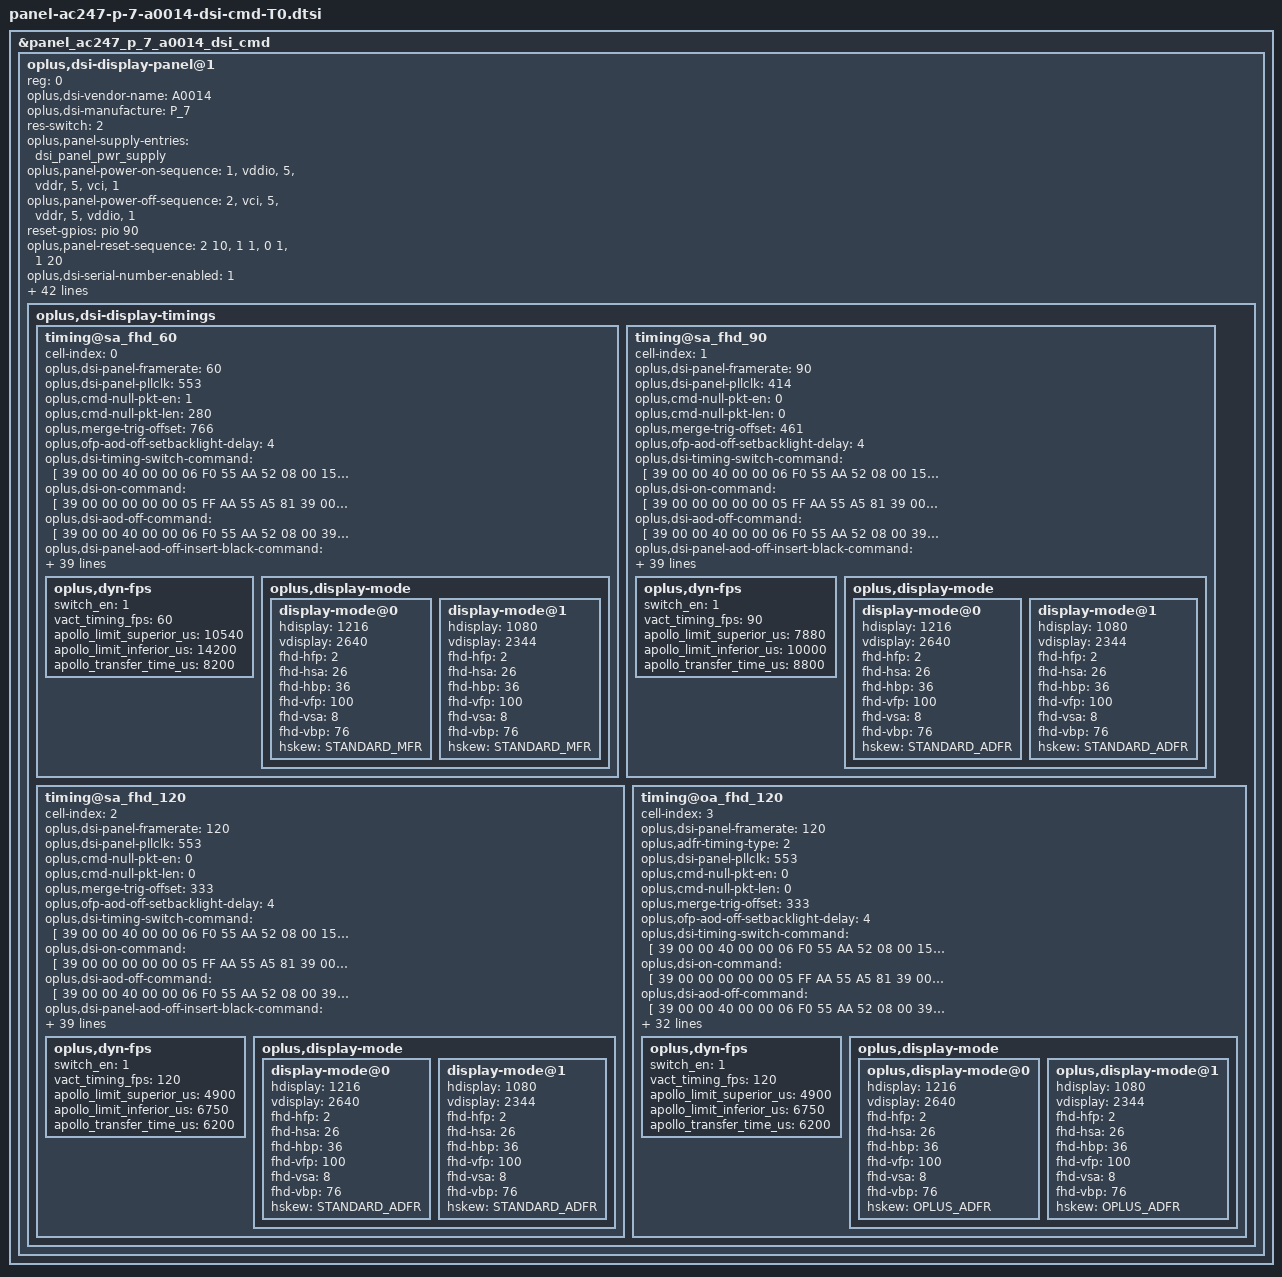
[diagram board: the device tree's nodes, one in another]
&panel_ac247_p_7_a0014_dsi_cmd {
	oplus,dsi-display-panel@1 {
		reg = <0>;
		oplus,dsi-vendor-name = "A0014";
		oplus,dsi-manufacture = "P_7";
		/* round corner */
		//#include "panel-ac247-p-7-a0014-dsi-cmd-round-corner.dtsi"
		oplus,dsi-display-timings {
			timing@sa_fhd_60 {
				cell-index = <0>;
				oplus,dsi-panel-framerate = <60>;
				oplus,dsi-panel-pllclk = <553>;
				oplus,cmd-null-pkt-en = <1>;
				oplus,cmd-null-pkt-len = <280>;
				oplus,merge-trig-offset = <766>;
				oplus,ofp-aod-off-setbacklight-delay = <4>;
				#include "panel-ac247-p-7-a0014-dsi-cmd-common-T0.dtsi"
				oplus,dsi-timing-switch-command = [
					//2F:30->6D:01 60Hz(Repeat 1 times) --> 60Hz
					39 00 00 40 00 00 06 F0 55 AA 52 08 00
					15 00 00 40 00 00 02 6F 03
					39 00 00 40 00 00 03 35 00 01
					15 00 00 40 00 00 02 6F 20
					39 00 00 40 00 00 09 BA 00 01 03 03 00 01 03 03
					15 00 00 40 00 00 02 6F 30
					39 00 00 40 00 00 09 BA 00 01 03 0B 00 01 03 0B
					15 00 00 40 00 00 02 6F 40
					39 00 00 40 00 00 09 BA 00 01 03 17 00 01 03 17
					15 00 00 40 00 00 02 6F 50
					39 00 00 40 00 00 09 BA 00 01 03 77 00 01 03 77
					15 00 00 40 00 00 02 2F 30
					15 00 00 40 00 00 02 6D 01 //60Hz
					// DC/PWM fix
					39 00 00 40 00 00 06 F0 55 AA 52 08 09
					15 00 00 40 00 00 02 6F 1C
					39 00 00 40 00 00 06 BD 90 87 82 06 1C //Comp0_R_Gray0~4_DBV1
					15 00 00 40 00 00 02 6F 21
					39 00 00 40 00 00 06 BD 90 87 82 06 1C //Comp0_R_Gray0~4_DBV2
					15 00 00 40 00 00 02 6F 26
					39 00 00 40 00 00 06 BD 0A 07 02 86 97 //Comp0_R_Gray0~4_DBV3
					15 00 00 40 00 00 02 6F 2B
					39 00 00 40 00 00 06 BD 0A 07 02 86 97 //Comp0_R_Gray0~4_DBV4
					15 00 00 40 00 00 02 6F 3A
					39 00 00 40 00 00 06 BD 90 87 82 06 1C //Comp0_G_Gray0~4_DBV1
					15 00 00 40 00 00 02 6F 3F
					39 00 00 40 00 00 06 BD 90 87 82 06 1C //Comp0_G_Gray0~4_DBV1
					15 00 00 40 00 00 02 6F 44
					39 00 00 40 00 00 06 BD 0A 07 02 86 97 //Comp0_G_Gray0~4_DBV3
					15 00 00 40 00 00 02 6F 49
					39 00 00 40 00 00 06 BD 0A 07 02 86 97 //Comp0_G_Gray0~4_DBV4
					15 00 00 40 00 00 02 6F 58
					39 00 00 40 00 00 06 BD 90 87 82 06 1C //Comp0_B_Gray0~4_DBV1
					15 00 00 40 00 00 02 6F 5D
					39 00 00 40 00 00 06 BD 90 87 82 06 1C //Comp0_B_Gray0~4_DBV1
					15 00 00 40 00 00 02 6F 62
					39 00 00 40 00 00 06 BD 0A 07 02 86 97 //Co mp0_B_Gray0~4_DBV3
					15 00 00 40 00 00 02 6F 67
					39 00 00 00 00 00 06 BD 0A 07 02 86 97 //Comp0_B_Gray0~4_DBV4
				];
				oplus,dsi-on-command = [
					// init code
					39 00 00 00 00 00 05 FF AA 55 A5 81
					39 00 00 00 00 00 02 6F 0C
					39 00 00 00 00 00 02 FD 08
					39 00 00 00 00 00 02 6F 02
					39 00 00 00 00 00 02 F9 84
					39 00 00 00 00 00 02 6F 10
					39 00 00 00 00 00 02 FB 40
					39 00 00 00 00 00 05 FF AA 55 A5 80
					39 00 00 00 00 00 02 6F 48
					39 00 00 00 00 00 02 F2 00
					39 00 00 00 00 00 05 FF AA 55 A5 80
					39 00 00 00 00 00 02 6F 16
					39 00 00 00 00 00 03 F4 02 74
					39 00 00 00 00 00 05 FF AA 55 A5 80
					39 00 00 00 00 00 02 6F 42
					39 00 00 00 00 00 02 F4 00
					39 00 00 00 00 00 05 FF AA 55 A5 80
					39 00 00 00 00 00 02 6F 49
					39 00 00 00 00 00 02 F2 10
					39 00 00 00 00 00 05 FF AA 55 A5 81
					39 00 00 00 00 00 02 6F 05
					39 00 00 00 00 00 03 FE 3C 3C
					39 00 00 00 00 00 05 FF AA 55 A5 82
					39 00 00 00 00 00 02 6F 09
					39 00 00 00 00 00 02 F2 FF
					39 00 00 00 00 00 05 FF AA 55 A5 80
					39 00 00 00 00 00 02 6F 04
					39 00 00 00 00 00 02 F2 3C
					39 00 00 00 00 00 05 FF AA 55 A5 80
					39 00 00 00 00 00 02 6F 0A
					39 00 00 00 00 00 06 F6 70 70 70 70 70 //Power seq
					39 00 00 00 00 00 05 FF AA 55 A5 81
					39 00 00 00 00 00 02 6F 0D
					39 00 00 00 00 00 02 FB 80 // TE_opt
					39 00 00 00 00 00 06 F0 55 AA 52 08 01
					39 00 00 00 00 00 02 E5 00
					39 00 00 00 00 00 05 FF AA 55 A5 80
					39 00 00 00 00 00 02 6F 15
					39 00 00 00 00 00 03 F8 01 8C // DSPOSC=138.6MHz
					39 00 00 00 00 00 05 FF AA 55 A5 80
					39 00 00 00 00 00 02 6F 3E
					39 00 00 00 00 00 02 F8 00
					39 00 00 00 00 00 05 FF AA 55 A5 81
					39 00 00 00 00 00 02 6F 0B
					39 00 00 00 00 00 02 FD 04
					39 00 00 00 00 00 02 5A 01
					39 00 00 00 00 00 02 17 30
					39 00 00 00 00 00 03 5F 00 00
					39 00 00 00 00 00 02 35 00 // TE on
					39 00 00 00 00 00 0A 88 01 02 5F 09 4F 00 00 00 00
					39 00 00 00 00 00 02 53 20
					39 00 00 00 00 00 05 2A 00 00 04 BF
					39 00 00 00 00 00 05 2B 00 00 0A 4F
					39 00 00 00 00 00 02 90 03
					39 00 00 00 00 00 02 6F 01
					39 00 00 00 00 00 02 90 43
					39 00 00 00 00 00 13 91 AB A8 00 14 C2 00 02 31 02 05 00 08 05 0E 04 7B 10 E0 // VESA
					39 00 00 00 00 00 02 26 00
					39 00 00 00 00 00 02 6D 00
					39 00 00 00 00 00 02 6F 06
					39 00 00 00 00 00 02 6D 00
					//Vporch Setting
					39 00 00 00 00 00 06 F0 55 AA 52 08 00
					39 00 00 00 00 00 08 BA 00 59 00 4C 00 64 10
					39 00 00 00 00 00 02 6F 07
					39 00 00 00 00 00 08 BA 00 59 00 4C 04 0C 10
					//Chopper Setting
					39 00 00 00 00 00 06 F0 55 AA 52 08 01
					39 00 00 00 00 00 05 D9 48 50 13 40
					39 00 00 00 00 00 02 6F 23
					39 00 00 00 00 00 04 D9 C1 49 13
					39 00 00 00 00 00 06 F0 55 AA 52 08 08 //alpha LUT
					39 00 00 00 00 00 02 6F 30
					39 00 00 00 00 00 15 B2 00 00 24 B8 2C A8 34 E8 3C 78 23 B7 29 D7 33 D7 3F 27 29 96
					39 00 00 00 00 00 02 6F 44
					39 00 00 00 00 00 15 B2 34 76 22 75 2A 65 32 95 21 E4 20 53 2C E3 2C C3 26 52 20 81
					39 00 00 00 00 00 02 6F 58
					39 00 00 00 00 00 0B B2 31 31 28 30 00 1F 00 1F 00 1F
					39 00 00 00 00 00 02 6F 00
					39 00 00 00 00 00 15 B2 00 01 00 38 00 6F 00 A6 00 DD 01 14 01 5E 01 82 01 B9 01 E0
					39 00 00 00 00 00 02 6F 14
					39 00 00 00 00 00 15 B2 02 27 02 5E 02 95 02 E4 03 E5 04 8A 04 8B 05 DC 07 50 08 FC
					39 00 00 00 00 00 02 6F 28
					39 00 00 00 00 00 09 B2 0B 17 0D BB 0F FE 0F FF
					//odc on/fix
					39 00 00 00 00 00 06 F0 55 AA 52 08 08
					39 00 00 00 00 00 05 E0 21 01 01 01
					15 00 00 00 00 00 02 6F 06
					39 00 00 00 00 00 08 E0 80 30 21 32 43 54 65
					15 00 00 00 00 00 02 6F 0D
					39 00 00 00 00 00 07 E0 76 87 98 99 99 09
					39 00 00 00 00 00 08 E1 00 00 00 00 00 00 00
					15 00 00 00 00 00 02 6F 07
					39 00 00 00 00 00 08 E1 00 00 00 00 00 00 00
					15 00 00 00 00 00 02 6F 0E
					39 00 00 00 00 00 08 E1 00 00 00 00 00 00 00
					15 00 00 00 00 00 02 6F 15
					39 00 00 00 00 00 08 E1 00 00 00 00 00 00 00
					15 00 00 00 00 00 02 6F 1C
					39 00 00 00 00 00 08 E1 00 00 00 00 00 00 00
					15 00 00 00 00 00 02 6F 23
					39 00 00 00 00 00 08 E1 00 00 00 00 00 00 00
					15 00 00 00 00 00 02 6F 2A
					39 00 00 00 00 00 08 E1 00 00 00 00 00 00 00
					15 00 00 00 00 00 02 6F 31
					39 00 00 00 00 00 08 E1 00 00 00 00 00 00 00
					15 00 00 00 00 00 02 6F 38
					39 00 00 00 00 00 08 E1 00 00 00 00 00 00 00
					15 00 00 00 00 00 02 6F 3F
					39 00 00 00 00 00 08 E1 00 00 00 00 00 00 00
					15 00 00 00 00 00 02 6F 46
					39 00 00 00 00 00 08 E1 00 00 00 00 00 00 00
					15 00 00 00 00 00 02 6F 4D
					39 00 00 00 00 00 08 E1 00 00 00 00 00 00 00
					15 00 00 00 00 00 02 6F 54
					39 00 00 00 00 00 08 E1 00 00 00 00 00 00 00
					15 00 00 00 00 00 02 6F 5B
					39 00 00 00 00 00 08 E1 00 00 00 00 00 00 00
					15 00 00 00 00 00 02 6F 62
					39 00 00 00 00 00 08 E1 00 00 00 00 00 00 00
					15 00 00 00 00 00 02 6F 69
					39 00 00 00 00 00 08 E1 00 00 00 00 00 00 00
					15 00 00 00 00 00 02 6F 70
					39 00 00 00 00 00 08 E1 00 00 00 00 00 00 00
					15 00 00 00 00 00 02 6F 77
					39 00 00 00 00 00 08 E1 00 00 00 00 00 00 00
					39 00 00 00 00 00 08 E2 00 00 00 00 00 00 00
					15 00 00 00 00 00 02 6F 07
					39 00 00 00 00 00 08 E2 00 00 00 00 00 00 00
					15 00 00 00 00 00 02 6F 0E
					39 00 00 00 00 00 08 E2 00 00 00 00 00 00 00
					15 00 00 00 00 00 02 6F 15
					39 00 00 00 00 00 08 E2 00 00 00 00 00 00 00
					15 00 00 00 00 00 02 6F 1C
					39 00 00 00 00 00 08 E2 00 00 00 00 00 00 00
					15 00 00 00 00 00 02 6F 23
					39 00 00 00 00 00 08 E2 00 00 00 00 00 00 00
					15 00 00 00 00 00 02 6F 2A
					39 00 00 00 00 00 08 E2 02 04 0A 07 08 08 08
					15 00 00 00 00 00 02 6F 31
					39 00 00 00 00 00 08 E2 02 04 0A 07 08 08 08
					15 00 00 00 00 00 02 6F 38
					39 00 00 00 00 00 08 E2 02 04 0A 07 08 08 08
					15 00 00 00 00 00 02 6F 3F
					39 00 00 00 00 00 08 E2 02 04 0A 07 08 08 08
					15 00 00 00 00 00 02 6F 46
					39 00 00 00 00 00 08 E2 00 00 06 01 03 06 08
					15 00 00 00 00 00 02 6F 4D
					39 00 00 00 00 00 08 E2 02 04 0A 07 08 08 08
					15 00 00 00 00 00 02 6F 54
					39 00 00 00 00 00 08 E2 06 06 06 06 06 06 06
					15 00 00 00 00 00 02 6F 5B
					39 00 00 00 00 00 08 E2 06 06 06 06 06 06 06
					15 00 00 00 00 00 02 6F 62
					39 00 00 00 00 00 08 E2 06 06 06 06 06 06 06
					15 00 00 00 00 00 02 6F 69
					39 00 00 00 00 00 08 E2 06 06 06 06 06 06 06
					15 00 00 00 00 00 02 6F 70
					39 00 00 00 00 00 08 E2 07 07 07 07 07 07 07
					15 00 00 00 00 00 02 6F 77
					39 00 00 00 00 00 08 E2 07 07 07 07 07 07 07
					39 00 00 00 00 00 08 E3 00 00 00 00 00 00 00
					15 00 00 00 00 00 02 6F 07
					39 00 00 00 00 00 08 E3 00 00 00 00 00 00 00
					15 00 00 00 00 00 02 6F 0E
					39 00 00 00 00 00 08 E3 00 00 00 00 00 00 00
					15 00 00 00 00 00 02 6F 15
					39 00 00 00 00 00 08 E3 00 00 00 00 00 00 00
					15 00 00 00 00 00 02 6F 1C
					39 00 00 00 00 00 08 E3 00 00 00 00 00 00 00
					15 00 00 00 00 00 02 6F 23
					39 00 00 00 00 00 08 E3 00 00 00 00 00 00 00
					15 00 00 00 00 00 02 6F 2A
					39 00 00 00 00 00 08 E3 00 00 00 00 00 00 00
					15 00 00 00 00 00 02 6F 31
					39 00 00 00 00 00 08 E3 00 00 00 00 00 00 00
					15 00 00 00 00 00 02 6F 38
					39 00 00 00 00 00 08 E3 00 00 00 00 00 00 00
					15 00 00 00 00 00 02 6F 3F
					39 00 00 00 00 00 08 E3 00 00 00 00 00 00 00
					15 00 00 00 00 00 02 6F 46
					39 00 00 00 00 00 08 E3 00 00 00 00 00 00 00
					15 00 00 00 00 00 02 6F 4D
					39 00 00 00 00 00 08 E3 00 00 00 00 00 00 00
					15 00 00 00 00 00 02 6F 54
					39 00 00 00 00 00 08 E3 00 00 00 00 00 00 00
					15 00 00 00 00 00 02 6F 5B
					39 00 00 00 00 00 08 E3 00 00 00 00 00 00 00
					15 00 00 00 00 00 02 6F 62
					39 00 00 00 00 00 08 E3 00 00 00 00 00 00 00
					15 00 00 00 00 00 02 6F 69
					39 00 00 00 00 00 08 E3 00 00 00 00 00 00 00
					15 00 00 00 00 00 02 6F 70
					39 00 00 00 00 00 08 E3 00 00 00 00 00 00 00
					15 00 00 00 00 00 02 6F 77
					39 00 00 00 00 00 08 E3 00 00 00 00 00 00 00
					39 00 00 00 00 00 08 EA 00 00 00 00 00 00 00
					15 00 00 00 00 00 02 6F 07
					39 00 00 00 00 00 08 EA 00 00 00 00 00 00 00
					15 00 00 00 00 00 02 6F 0E
					39 00 00 00 00 00 08 EA 00 00 00 00 00 00 00
					15 00 00 00 00 00 02 6F 15
					39 00 00 00 00 00 07 EA 00 00 00 00 00 00
					39 00 00 00 00 00 08 E4 00 00 00 00 00 00 00
					15 00 00 00 00 00 02 6F 07
					39 00 00 00 00 00 03 E4 00 00
					39 00 00 00 00 00 08 E5 00 00 00 00 00 00 00
					15 00 00 00 00 00 02 6F 07
					39 00 00 00 00 00 03 E5 00 00
					39 00 00 00 00 00 08 E6 00 00 00 00 00 00 00
					15 00 00 00 00 00 02 6F 07
					39 00 00 00 00 00 03 E6 00 00
					39 00 00 00 00 00 08 E8 11 90 00 00 00 20 00
					15 00 00 00 00 00 02 6F 07
					39 00 00 00 00 00 08 E8 68 6C 6C 70 70 74 74
					15 00 00 00 00 00 02 6F 0E
					39 00 00 00 00 00 08 E8 78 78 7D 7D A0 A0 A1
					15 00 00 00 00 00 02 6F 15
					39 00 00 00 00 00 08 E8 A1 A1 A1 98 98 99 99
					15 00 00 00 00 00 02 6F 1C
					39 00 00 00 00 00 08 E8 99 00 48 4D 4D 4E 4E
					15 00 00 00 00 00 02 6F 23
					39 00 00 00 00 00 08 E8 52 52 56 56 5A 5A 90
					15 00 00 00 00 00 02 6F 2A
					39 00 00 00 00 00 08 E8 90 90 90 90 90 8D 8D
					15 00 00 00 00 00 02 6F 31
					39 00 00 00 00 00 08 E8 89 89 89 00 A8 AA AA
					15 00 00 00 00 00 02 6F 38
					39 00 00 00 00 00 08 E8 AA AA AA AA AB AB AD
					15 00 00 00 00 00 02 6F 3F
					39 00 00 00 00 00 08 E8 AD B8 B8 B8 B8 B8 B8
					15 00 00 00 00 00 02 6F 46
					39 00 00 00 00 00 06 E8 B5 B5 B3 B3 B0
					// serinal number
					39 00 00 00 00 00 06 F0 55 AA 52 08 01
					39 00 00 00 00 00 08 D7 3B 1B 17 24 2F 00 62
					// corner improve
					39 00 00 00 00 00 06 F0 55 AA 52 08 07
					39 00 00 00 00 00 04 C0 07 01 F8
					15 00 00 00 00 00 02 6F 03
					39 00 00 00 00 00 05 C0 00 F0 00 00
					39 00 00 00 00 00 16 C1 3C 00 0C B1 07 39 13 26 3F E7 D0 00 00 00 00 00 00 00 00 00 00
					15 00 00 00 00 00 02 6F 15
					39 00 00 00 00 00 11 C1 83 00 00 2B 9A 9A 21 33 C0 79 2B 00 00 00 00 00
					15 00 00 00 00 00 02 6F 25
					39 00 00 00 00 00 08 C1 00 26 2B AA 22 26 00
					39 00 00 00 00 00 16 C2 3C 00 07 E9 0E 89 15 72 3F F3 84 4C 00 0B 18 A0 00 00 00 00 00
					15 00 00 00 00 00 02 6F 15
					39 00 00 00 00 00 11 C2 04 00 2C B9 AA 22 4F 33 C0 D3 8D 00 00 00 00 00
					15 00 00 00 00 00 02 6F 25
					39 00 00 00 00 00 08 C2 44 94 9A AA 22 29 00
					39 00 00 00 00 00 16 C3 3A 0F 0B 64 06 91 EE B4 00 13 8D 68 00 03 26 1C 7F FC 64 FA 44
					15 00 00 00 00 00 02 6F 15
					39 00 00 00 00 00 11 C3 89 44 94 BF 9A 97 21 33 0F 8A 2B E8 D2 00 00 00
					15 00 00 00 00 00 02 6F 25
					39 00 00 00 00 00 08 C3 00 26 2B 00 29 2D 00
					39 00 00 00 00 00 16 C4 32 0F 07 39 07 E9 F0 E2 00 02 E5 72 00 12 B9 8E 7F FC 76 CF F9
					15 00 00 00 00 00 02 6F 15
					39 00 00 00 00 00 11 C4 2D 44 0C 93 AA 22 4F 33 0F 2D 87 E8 45 00 00 00
					15 00 00 00 00 00 02 6F 25
					39 00 00 00 00 00 08 C4 44 94 99 00 29 2D 00
					39 00 00 00 00 00 16 C5 30 0F 0B D1 07 39 ED 86 3F F2 0E AA 3F F8 61 E2 00 02 02 30 E9
					15 00 00 00 00 00 02 6F 15
					39 00 00 00 00 00 11 C5 02 00 00 2B 00 2E B5 33 F0 79 D5 16 AD 00 00 00
					15 00 00 00 00 00 02 6F 25
					39 00 00 00 00 00 08 C5 44 94 9A 00 26 2D 00
					39 00 00 00 00 00 16 C6 20 0F 07 E9 07 39 F0 E2 3F F7 A8 42 3F F2 37 5E 00 02 33 22 99
					15 00 00 00 00 00 02 6F 15
					39 00 00 00 00 00 11 C6 2D 00 2C B3 00 00 2D 33 F0 D3 79 17 BB 00 00 00
					15 00 00 00 00 00 02 6F 25
					39 00 00 00 00 00 08 C6 00 00 00 00 00 00 00
					39 00 00 00 00 00 16 C7 2E 00 08 A1 07 39 0F CA 00 0A DD 90 3F F5 9E 10 00 00 00 00 00
					15 00 00 00 00 00 02 6F 15
					39 00 00 00 00 00 11 C7 89 44 94 BF 00 2E B7 33 30 89 D5 00 00 00 00 00
					15 00 00 00 00 00 02 6F 25
					39 00 00 00 00 00 08 C7 00 00 00 00 00 00 00
					39 00 00 00 00 00 16 C8 26 00 07 E9 0C B1 14 0A 00 00 00 00 3F E6 B0 00 00 00 00 00 00
					15 00 00 00 00 00 02 6F 15
					39 00 00 00 00 00 11 C8 27 44 0C 93 00 00 2D 33 30 2D 79 00 00 00 00 00
					15 00 00 00 00 00 02 6F 25
					39 00 00 00 00 00 08 C8 00 00 00 00 00 00 00
					39 00 00 00 00 00 16 C9 21 00 05 A4 05 59 00 00 3F FE 5E 98 3F FE 69 94 00 00 1E 2A 04
					15 00 00 00 00 00 02 6F 15
					39 00 00 00 00 00 11 C9 0A 22 3A 5F 00 28 4E 33 F0 DA DB 05 7E 00 00 00
					15 00 00 00 00 00 02 6F 25
					39 00 00 00 00 00 08 C9 00 00 00 00 00 00 00
					39 00 00 00 00 00 16 CA 2D 00 05 A4 05 59 00 00 3F FE 5E 98 00 00 00 00 00 00 00 00 00
					15 00 00 00 00 00 02 6F 15
					39 00 00 00 00 00 11 CA 1B 22 3A 5F 00 4F 75 33 C0 DA 25 00 00 00 00 00
					15 00 00 00 00 00 02 6F 25
					39 00 00 00 00 00 08 CA 00 00 00 00 00 00 00
					39 00 00 00 00 00 16 CB 2B 00 05 A4 05 59 00 00 00 00 00 00 00 00 00 00 7F FF E1 D5 FC
					15 00 00 00 00 00 02 6F 15
					39 00 00 00 00 00 11 CB 1B 22 60 85 00 4F 75 33 0F 26 25 FA 82 00 00 00
					15 00 00 00 00 00 02 6F 25
					39 00 00 00 00 00 08 CB 00 00 00 00 00 00 00
					39 00 00 00 00 00 16 CC 27 00 05 A4 05 59 00 00 00 00 00 00 3F FE 69 94 00 00 00 00 00
					15 00 00 00 00 00 02 6F 15
					39 00 00 00 00 00 11 CC 0A 22 60 85 00 28 4E 33 30 26 DB 00 00 00 00 00
					15 00 00 00 00 00 02 6F 25
					39 00 00 00 00 00 08 CC 00 00 00 00 00 00 00
					39 00 00 00 00 00 16 CD 21 00 27 10 27 10 00 00 3F E1 7B 80 3F E1 7B 80 00 05 F5 E1 00
					15 00 00 00 00 00 02 6F 15
					39 00 00 00 00 00 11 CD 1D 12 FA 5E 89 EB 4F 33 F0 9C 9C 27 10 00 00 00
					15 00 00 00 00 00 02 6F 25
					39 00 00 00 00 00 08 CD 00 00 00 00 00 00 00
					39 00 00 00 00 00 16 CE 27 00 27 10 27 10 00 00 00 00 00 00 3F E1 7B 80 00 00 00 00 00
					15 00 00 00 00 00 02 6F 15
					39 00 00 00 00 00 11 CE 1D 22 5F C3 89 EB 4F 33 30 64 9C 00 00 00 00 00
					15 00 00 00 00 00 02 6F 25
					39 00 00 00 00 00 08 CE 00 00 00 00 00 00 00
					39 00 00 00 00 00 16 CF 2D 00 27 10 27 10 00 00 3F E1 7B 80 00 00 00 00 00 00 00 00 00
					15 00 00 00 00 00 02 6F 15
					39 00 00 00 00 00 11 CF 46 12 FA 5E 99 50 B4 33 C0 9C 64 00 00 00 00 00
					15 00 00 00 00 00 02 6F 25
					39 00 00 00 00 00 08 CF 00 00 00 00 00 00 00
					39 00 00 00 00 00 16 D0 2B 00 27 10 27 10 00 00 00 00 00 00 00 00 00 00 7F FA 0A 1F 00
					15 00 00 00 00 00 02 6F 15
					39 00 00 00 00 00 11 D0 46 22 5F C3 99 50 B4 33 0F 64 64 D8 F0 00 00 00
					15 00 00 00 00 00 02 6F 25
					39 00 00 00 00 00 08 D0 00 00 00 00 00 00 00
					39 00 00 00 00 00 0F D1 7F FC 4B 9A 69 04 BF 7F FB 86 2B AD 04 BF
					15 00 00 00 00 00 02 6F 0E
					39 00 00 00 00 00 0F D1 00 00 00 00 00 04 C0 00 00 00 00 00 04 C0
					15 00 00 00 00 00 02 6F 1C
					39 00 00 00 00 00 0F D1 80 00 00 00 00 04 BF 80 00 00 00 00 04 BF
					15 00 00 00 00 00 02 6F 2A
					39 00 00 00 00 00 0C D1 00 02 11 8A 09 00 00 00 02 33 22
					39 00 00 00 00 00 12 D2 99 00 00 00 00 00 00 00 04 C0 7F FF E1 D5 FC 04 C0
					39 00 00 00 00 00 06 F0 55 AA 52 08 00
					15 00 00 00 00 00 02 6F 13
					39 00 00 00 00 00 19 DF 02 5E 09 4F 00 00 00 00 01 FA 08 EB 02 C3 09 B4 00 00 00 00 00 00 00 00
					//skip sequence
					39 00 00 00 00 00 06 F0 55 AA 52 08 00
					39 00 00 00 00 00 02 6F 1C
					39 00 00 00 00 00 11 BA 01 01 01 01 00 01 03 03 00 01 03 03 00 00 00 00
					39 00 00 00 00 00 02 6F 2C
					39 00 00 00 00 00 11 BA 01 01 01 01 00 01 03 0B 00 01 03 0B 00 00 00 00
					39 00 00 00 00 00 02 6F 3C
					39 00 00 00 00 00 11 BA 01 01 01 01 00 01 03 17 00 01 03 17 00 00 00 00
					39 00 00 00 00 00 02 6F 4C
					39 00 00 00 00 00 11 BA 01 01 01 01 00 01 03 77 00 01 03 77 00 00 00 00
					39 00 00 00 00 00 02 6F 5C
					39 00 00 00 00 00 11 BA 01 01 01 01 01 01 01 01 01 01 01 01 01 01 01 01
					39 00 00 00 00 00 02 6F 6C
					39 00 00 00 00 00 09 BA 00 00 00 00 00 00 00 00
					39 00 00 00 00 00 02 6F 74
					39 00 00 00 00 00 11 BA 00 01 02 03 05 0B 17 77 00 01 02 05 08 11 59 00
					39 00 00 00 00 00 02 6F 84
					39 00 00 00 00 00 11 BA 00 01 02 03 05 0B 17 77 00 01 02 05 08 11 59 00
					39 00 00 00 00 00 02 6F 94
					39 00 00 00 00 00 11 BA 00 00 00 00 00 00 00 00 00 00 00 00 00 00 00 00
					39 00 00 00 00 00 02 6F A4
					39 00 00 00 00 00 11 BA 01 01 01 01 00 00 00 02 00 00 00 03 00 00 00 00
					39 00 00 00 00 00 02 6F B4
					39 00 00 00 00 00 05 BA 94 FA A4 3A
					39 00 00 00 00 00 02 6F B8
					39 00 00 00 00 00 09 BA 00 00 00 00 11 11 11 11
					39 00 00 00 00 00 02 6F C0
					39 00 00 00 00 00 09 BA 10 00 00 00 11 11 11 11
					39 00 00 00 00 00 02 6F 08
					39 00 00 00 00 00 05 BB 01 00 00 00
					39 00 00 00 00 00 02 6F 0C
					39 00 00 00 00 00 05 BB 01 02 02 00
					39 00 00 00 00 00 02 6F 10
					39 00 00 00 00 00 05 BB 01 05 05 00
					39 00 00 00 00 00 02 6F 14
					39 00 00 00 00 00 05 BB 01 00 00 00
					39 00 00 00 00 00 02 6F 18
					39 00 00 00 00 00 06 BB 01 00 1D 1D 00
					39 00 00 00 00 00 02 6F 1D
					39 00 00 00 00 00 05 BB 01 01 01 00
					15 00 00 00 00 00 02 6F 1E
					15 00 00 00 00 00 02 B5 19 // AOD discharge on DVT OTP
					39 00 00 00 00 00 06 F0 55 AA 52 08 08
					15 00 00 00 00 00 02 6F AC
					39 00 00 00 00 00 05 BC 00 10 10 00 // OD beta3 off DVT OTP
					// VFP/VBP SOP/GOP ON
					39 00 00 00 00 00 06 F0 55 AA 52 08 00
					15 00 00 00 00 00 02 6F 0D
					15 00 00 00 00 00 02 C2 0F
					//OSC：121.9-121.2 MHz
					39 00 00 00 00 00 05 FF AA 55 A5 80
					15 00 00 00 00 00 02 6F 31
					39 00 00 00 00 00 03 F8 01 B7
					// LFCC fix
					39 00 00 00 00 00 06 F0 55 AA 52 08 00
					15 00 00 00 00 00 02 6F 08
					15 00 00 00 00 00 02 B2 C0
					39 00 00 00 00 00 06 F0 55 AA 52 08 09
					//Comp_DBVPNTS0~5 = 423h,424h,48Ah,48Bh,4F0h,4F1h
					15 00 00 00 00 00 02 6F 01
					39 00 00 00 00 00 0A BD 44 23 24 44 8A 8B 44 F0 F1
					// Fixed TE
					15 00 00 00 00 00 02 5A 00
					15 00 00 00 00 00 02 6F 03
					15 00 00 00 00 00 02 5A 00
					39 00 00 00 00 00 03 44 00 00
					15 00 00 00 00 00 02 6F 04
					39 00 00 00 00 00 0D 44 00 00 00 00 00 00 00 00 00 00 00 00
					39 00 00 00 00 00 06 F0 55 AA 52 08 00
					15 00 00 00 00 00 02 BE 47
					// TEST TE
					39 00 00 00 00 00 06 F0 55 AA 52 08 00
					15 00 00 00 00 00 02 6F 01
					15 00 00 00 00 00 02 BE 54
					//2F:30->6D:01 60Hz(Repeat 1 times) --> 60Hz
					39 00 00 00 00 00 06 F0 55 AA 52 08 00
					15 00 00 00 00 00 02 6F 03
					39 00 00 00 00 00 03 35 00 01
					15 00 00 00 00 00 02 6F 20
					39 00 00 00 00 00 09 BA 00 01 03 03 00 01 03 03
					15 00 00 00 00 00 02 6F 30
					39 00 00 00 00 00 09 BA 00 01 03 0B 00 01 03 0B
					15 00 00 00 00 00 02 6F 40
					39 00 00 00 00 00 09 BA 00 01 03 17 00 01 03 17
					15 00 00 00 00 00 02 6F 50
					39 00 00 00 00 00 09 BA 00 01 03 77 00 01 03 77
					15 00 00 00 00 00 02 2F 30
					15 00 00 00 00 00 02 6D 01 //60Hz
					// DC/PWM fix
					39 00 00 00 00 00 06 F0 55 AA 52 08 09
					15 00 00 00 00 00 02 6F 1C
					39 00 00 00 00 00 06 BD 90 87 82 06 1C //Comp0_R_Gray0~4_DBV1
					15 00 00 00 00 00 02 6F 21
					39 00 00 00 00 00 06 BD 90 87 82 06 1C //Comp0_R_Gray0~4_DBV2
					15 00 00 00 00 00 02 6F 26
					39 00 00 00 00 00 06 BD 0A 07 02 86 97 //Comp0_R_Gray0~4_DBV3
					15 00 00 00 00 00 02 6F 2B
					39 00 00 00 00 00 06 BD 0A 07 02 86 97 //Comp0_R_Gray0~4_DBV4
					15 00 00 00 00 00 02 6F 3A
					39 00 00 00 00 00 06 BD 90 87 82 06 1C //Comp0_G_Gray0~4_DBV1
					15 00 00 00 00 00 02 6F 3F
					39 00 00 00 00 00 06 BD 90 87 82 06 1C //Comp0_G_Gray0~4_DBV1
					15 00 00 00 00 00 02 6F 44
					39 00 00 00 00 00 06 BD 0A 07 02 86 97 //Comp0_G_Gray0~4_DBV3
					15 00 00 00 00 00 02 6F 49
					39 00 00 00 00 00 06 BD 0A 07 02 86 97 //Comp0_G_Gray0~4_DBV4
					15 00 00 00 00 00 02 6F 58
					39 00 00 00 00 00 06 BD 90 87 82 06 1C //Comp0_B_Gray0~4_DBV1
					15 00 00 00 00 00 02 6F 5D
					39 00 00 00 00 00 06 BD 90 87 82 06 1C //Comp0_B_Gray0~4_DBV1
					15 00 00 00 00 00 02 6F 62
					39 00 00 00 00 00 06 BD 0A 07 02 86 97 //Co mp0_B_Gray0~4_DBV3
					15 00 00 00 00 00 02 6F 67
					39 00 00 00 00 00 06 BD 0A 07 02 86 97 //Comp0_B_Gray0~4_DBV4
					//osc fixed
					39 00 00 00 00 00 06 F0 55 AA 52 08 01
					39 00 00 00 00 00 06 C3 DD 06 20 11 FF
					15 00 00 00 00 00 02 6F 05
					39 00 00 00 00 00 06 C3 00 06 20 11 FF
					15 00 00 00 00 00 02 6F 0A
					39 00 00 00 00 00 06 C3 00 07 0E 20 06
					15 00 00 00 00 00 02 6F 0F
					39 00 00 00 00 00 06 C3 44 19 07 11 18
					15 00 00 00 00 00 02 6F 14
					39 00 00 00 00 00 06 C3 06 5C 13 07 0E
					15 00 00 00 00 00 02 6F 19
					39 00 00 00 00 00 06 C3 20 06 44 19 07
					15 00 00 00 00 00 02 6F 1E
					39 00 00 00 00 00 06 C3 0E 20 06 44 19
					15 00 00 00 00 00 02 6F 23
					39 00 00 00 00 00 06 C3 07 0E 20 06 44
					15 00 00 00 00 00 02 6F 28
					15 00 00 00 00 00 02 C3 19
					//Modify power-off timing
					39 00 00 00 00 00 06 F0 55 AA 52 08 03
					15 00 00 00 00 00 02 6F 07
					15 00 00 00 00 00 02 C6 48
					//Light On
					39 00 00 00 78 00 01 11 // Sleep out
					39 00 00 00 00 00 01 29 // Display out
				];
				oplus,dsi-aod-off-command = [
					39 00 00 40 00 00 06 F0 55 AA 52 08 00
					39 00 00 40 00 00 02 2F 30
					39 00 00 40 00 00 02 6F 03
					39 00 00 40 00 00 03 35 00 01
					39 00 00 40 00 00 02 38 00
					05 00 00 40 00 00 01 2C
					39 00 00 40 00 00 03 51 00 00
					39 00 00 40 00 00 06 F0 55 AA 52 08 08
					39 00 00 40 00 00 02 BE 03
					39 00 00 40 00 00 05 FF AA 55 A5 81
					39 00 00 40 00 00 02 6F 0B
					39 00 00 00 00 00 02 FD 04 //gmaconv on
				];
				oplus,dsi-panel-aod-off-insert-black-command = [
					39 00 00 40 00 00 06 F0 55 AA 52 08 00
					39 00 00 40 00 00 02 C0 66
					39 00 00 40 00 00 06 F0 55 AA 52 08 01
					39 00 00 40 00 00 06 D2 00 11 00 00 15
					39 00 00 40 00 00 02 2F 30
					39 00 00 40 00 00 02 6F 03
					39 00 00 40 00 00 03 35 00 01
					39 00 00 40 00 00 02 38 00
					39 00 00 00 00 00 03 51 00 00
				];
				oplus,dsi-ultra-low-power-aod-on-command = [
					39 00 00 40 00 00 06 F0 55 AA 52 08 00
					39 00 00 40 00 00 02 6F 18
					39 00 00 00 00 00 06 BB 01 00 02 02 00
				];
				oplus,dsi-ultra-low-power-aod-off-command = [
					39 00 00 40 00 00 06 F0 55 AA 52 08 00
					39 00 00 40 00 00 02 6F 18
					39 00 00 00 00 00 06 BB 01 00 00 00 00
				];
				oplus,dsi-hbm-on-command = [
					39 00 00 00 00 00 03 51 0F FE
				];
				oplus,dsi-hbm-off-command = [
					39 00 00 00 00 00 03 51 0D BB
				];
				oplus,dsi-adfr-min-fps-60hz-command = [
					39 00 00 40 00 00 06 F0 55 AA 52 08 09
					15 00 00 40 00 00 02 6F 1C
					39 00 00 40 00 00 06 BD 90 87 82 06 1C
					15 00 00 40 00 00 02 6F 21
					39 00 00 40 00 00 06 BD 90 87 82 06 1C
					15 00 00 40 00 00 02 6F 26
					39 00 00 40 00 00 06 BD 0A 07 02 86 97
					15 00 00 40 00 00 02 6F 2B
					39 00 00 40 00 00 06 BD 0A 07 02 86 97
					15 00 00 40 00 00 02 6F 3A
					39 00 00 40 00 00 06 BD 90 87 82 06 1C
					15 00 00 40 00 00 02 6F 3F
					39 00 00 40 00 00 06 BD 90 87 82 06 1C
					15 00 00 40 00 00 02 6F 44
					39 00 00 40 00 00 06 BD 0A 07 02 86 97
					15 00 00 40 00 00 02 6F 49
					39 00 00 40 00 00 06 BD 0A 07 02 86 97
					15 00 00 40 00 00 02 6F 58
					39 00 00 40 00 00 06 BD 90 87 82 06 1C
					15 00 00 40 00 00 02 6F 5D
					39 00 00 40 00 00 06 BD 90 87 82 06 1C
					15 00 00 40 00 00 02 6F 62
					39 00 00 40 00 00 06 BD 0A 07 02 86 97
					15 00 00 40 00 00 02 6F 67
					39 00 00 40 00 00 06 BD 0A 07 02 86 97
					39 00 00 40 00 00 02 2F 30
					39 00 00 00 00 00 02 6D 01
				];
				oplus,dsi-adfr-min-fps-30hz-command = [
					39 00 00 40 00 00 06 F0 55 AA 52 08 09
					15 00 00 40 00 00 02 6F 1C
					39 00 00 40 00 00 06 BD 90 87 82 06 1C
					15 00 00 40 00 00 02 6F 21
					39 00 00 40 00 00 06 BD 90 87 82 06 1C
					15 00 00 40 00 00 02 6F 26
					39 00 00 40 00 00 06 BD 0A 07 02 86 97
					15 00 00 40 00 00 02 6F 2B
					39 00 00 40 00 00 06 BD 0A 07 02 86 97
					15 00 00 40 00 00 02 6F 3A
					39 00 00 40 00 00 06 BD 90 87 82 06 1C
					15 00 00 40 00 00 02 6F 3F
					39 00 00 40 00 00 06 BD 90 87 82 06 1C
					15 00 00 40 00 00 02 6F 44
					39 00 00 40 00 00 06 BD 0A 07 02 86 97
					15 00 00 40 00 00 02 6F 49
					39 00 00 40 00 00 06 BD 0A 07 02 86 97
					15 00 00 40 00 00 02 6F 58
					39 00 00 40 00 00 06 BD 90 87 82 06 1C
					15 00 00 40 00 00 02 6F 5D
					39 00 00 40 00 00 06 BD 90 87 82 06 1C
					15 00 00 40 00 00 02 6F 62
					39 00 00 40 00 00 06 BD 0A 07 02 86 97
					15 00 00 40 00 00 02 6F 67
					39 00 00 40 00 00 06 BD 0A 07 02 86 97
					39 00 00 40 00 00 02 2F 30
					39 00 00 00 00 00 02 6D 03
				];
				oplus,dsi-adfr-min-fps-10hz-command = [
					39 00 00 40 00 00 06 F0 55 AA 52 08 09
					15 00 00 40 00 00 02 6F 1C
					39 00 00 40 00 00 06 BD 90 87 82 06 1C
					15 00 00 40 00 00 02 6F 21
					39 00 00 40 00 00 06 BD 90 87 82 06 1C
					15 00 00 40 00 00 02 6F 26
					39 00 00 40 00 00 06 BD 0A 07 02 86 97
					15 00 00 40 00 00 02 6F 2B
					39 00 00 40 00 00 06 BD 0A 07 02 86 97
					15 00 00 40 00 00 02 6F 3A
					39 00 00 40 00 00 06 BD 90 87 82 06 1C
					15 00 00 40 00 00 02 6F 3F
					39 00 00 40 00 00 06 BD 90 87 82 06 1C
					15 00 00 40 00 00 02 6F 44
					39 00 00 40 00 00 06 BD 0A 07 02 86 97
					15 00 00 40 00 00 02 6F 49
					39 00 00 40 00 00 06 BD 0A 07 02 86 97
					15 00 00 40 00 00 02 6F 58
					39 00 00 40 00 00 06 BD 90 87 82 06 1C
					15 00 00 40 00 00 02 6F 5D
					39 00 00 40 00 00 06 BD 90 87 82 06 1C
					15 00 00 40 00 00 02 6F 62
					39 00 00 40 00 00 06 BD 0A 07 02 86 97
					15 00 00 40 00 00 02 6F 67
					39 00 00 40 00 00 06 BD 0A 07 02 86 97
					39 00 00 40 00 00 02 2F 30
					39 00 00 00 00 00 02 6D 05
				];
				oplus,dsi-adfr-min-fps-1hz-command = [
					39 00 00 40 00 00 06 F0 55 AA 52 08 09
					15 00 00 40 00 00 02 6F 1C
					39 00 00 40 00 00 06 BD 90 87 82 06 1C
					15 00 00 40 00 00 02 6F 21
					39 00 00 40 00 00 06 BD 90 87 82 06 1C
					15 00 00 40 00 00 02 6F 26
					39 00 00 40 00 00 06 BD 0A 07 02 86 97
					15 00 00 40 00 00 02 6F 2B
					39 00 00 40 00 00 06 BD 0A 07 02 86 97
					15 00 00 40 00 00 02 6F 3A
					39 00 00 40 00 00 06 BD 90 87 82 06 1C
					15 00 00 40 00 00 02 6F 3F
					39 00 00 40 00 00 06 BD 90 87 82 06 1C
					15 00 00 40 00 00 02 6F 44
					39 00 00 40 00 00 06 BD 0A 07 02 86 97
					15 00 00 40 00 00 02 6F 49
					39 00 00 40 00 00 06 BD 0A 07 02 86 97
					15 00 00 40 00 00 02 6F 58
					39 00 00 40 00 00 06 BD 90 87 82 06 1C
					15 00 00 40 00 00 02 6F 5D
					39 00 00 40 00 00 06 BD 90 87 82 06 1C
					15 00 00 40 00 00 02 6F 62
					39 00 00 40 00 00 06 BD 0A 07 02 86 97
					15 00 00 40 00 00 02 6F 67
					39 00 00 40 00 00 06 BD 0A 07 02 86 97
					39 00 00 40 00 00 02 2F 30
					39 00 00 00 00 00 02 6D 07
				];
				oplus,dsi-timing-switch-command-state = "dsi_hs_mode";
				oplus,dsi-on-command-state = "dsi_lp_mode";
				oplus,dsi-aod-off-command-state = "dsi_ls_mode";
				oplus,dsi-panel-aod-off-insert-black-command-state = "dsi_ls_mode";
				oplus,dsi-ultra-low-power-aod-on-command-state = "dsi_ls_mode";
				oplus,dsi-ultra-low-power-aod-off-command-state = "dsi_ls_mode";
				oplus,dsi-hbm-on-command-state = "dsi_hs_mode";
				oplus,dsi-hbm-off-command-state = "dsi_hs_mode";
				oplus,dsi-adfr-min-fps-60hz-command-state = "dsi_hs_mode";
				oplus,dsi-adfr-min-fps-30hz-command-state = "dsi_hs_mode";
				oplus,dsi-adfr-min-fps-10hz-command-state = "dsi_hs_mode";
				oplus,dsi-adfr-min-fps-1hz-command-state = "dsi_hs_mode";
				oplus,dsc-params-entries = <&dsc_params>;
				oplus,spr-params-entries = <&spr_params>;
				oplus,dyn-fps {
					switch_en = <1>;
					vact_timing_fps = <60>;
					apollo_limit_superior_us = <10540>;
					apollo_limit_inferior_us = <14200>;
					apollo_transfer_time_us = <8200>;
				};
				oplus,display-mode {
					display-mode@0 {
						hdisplay = <1216>;
						vdisplay = <2640>;
						fhd-hfp = <2>;
						fhd-hsa = <26>;
						fhd-hbp = <36>;
						fhd-vfp = <100>;
						fhd-vsa = <8>;
						fhd-vbp = <76>;
						hskew = <STANDARD_MFR>;
					};
					display-mode@1 {
						hdisplay = <1080>;
						vdisplay = <2344>;
						fhd-hfp = <2>;
						fhd-hsa = <26>;
						fhd-hbp = <36>;
						fhd-vfp = <100>;
						fhd-vsa = <8>;
						fhd-vbp = <76>;
						hskew = <STANDARD_MFR>;
					};
				};
			};
			timing@sa_fhd_90 {
				cell-index = <1>;
				oplus,dsi-panel-framerate = <90>;
				oplus,dsi-panel-pllclk = <414>;
				oplus,cmd-null-pkt-en = <0>;
				oplus,cmd-null-pkt-len = <0>;
				oplus,merge-trig-offset = <461>;
				oplus,ofp-aod-off-setbacklight-delay = <4>;
				#include "panel-ac247-p-7-a0014-dsi-cmd-common-T0.dtsi"
				oplus,dsi-timing-switch-command = [
					//90HZ
					39 00 00 40 00 00 06 F0 55 AA 52 08 00
					15 00 00 40 00 00 02 6F 03
					39 00 00 40 00 00 03 35 00 00
					15 00 00 40 00 00 02 6F 20
					39 00 00 40 00 00 09 BA 00 01 02 02 00 01 02 02
					15 00 00 40 00 00 02 6F 30
					39 00 00 40 00 00 09 BA 00 01 02 08 00 01 02 08
					15 00 00 40 00 00 02 6F 40
					39 00 00 40 00 00 09 BA 00 01 02 11 00 01 02 11
					15 00 00 40 00 00 02 6F 50
					39 00 00 40 00 00 09 BA 00 01 02 59 00 01 02 59
					15 00 00 40 00 00 02 2F 31
					15 00 00 40 00 00 02 6D 08 //90Hz
					// DC/PWM fix
					39 00 00 40 00 00 06 F0 55 AA 52 08 09
					15 00 00 40 00 00 02 6F 1C
					39 00 00 40 00 00 06 BD 98 89 84 02 15 //Comp0_R_Gray0~4_DBV1
					15 00 00 40 00 00 02 6F 21
					39 00 00 40 00 00 06 BD 98 89 84 02 15 //Comp0_R_Gray0~4_DBV2
					15 00 00 40 00 00 02 6F 26
					39 00 00 40 00 00 06 BD 12 09 04 86 97 //Comp0_R_Gray0~4_DBV3
					15 00 00 40 00 00 02 6F 2B
					39 00 00 40 00 00 06 BD 12 09 04 86 97 //Comp0_R_Gray0~4_DBV4
					15 00 00 40 00 00 02 6F 3A
					39 00 00 40 00 00 06 BD 98 89 84 02 15 //Comp0_G_Gray0~4_DBV1
					15 00 00 40 00 00 02 6F 3F
					39 00 00 40 00 00 06 BD 98 89 84 02 15 //Comp0_G_Gray0~4_DBV1
					15 00 00 40 00 00 02 6F 44
					39 00 00 40 00 00 06 BD 12 09 04 86 97 //Comp0_G_Gray0~4_DBV3
					15 00 00 40 00 00 02 6F 49
					39 00 00 40 00 00 06 BD 12 09 04 86 97 //Comp0_G_Gray0~4_DBV4
					15 00 00 40 00 00 02 6F 58
					39 00 00 40 00 00 06 BD 98 89 84 02 15 //Comp 0_B_Gray0~4_DBV1
					15 00 00 40 00 00 02 6F 5D
					39 00 00 40 00 00 06 BD 98 89 84 02 15 //Comp0_B_Gray0~4_DBV1
					15 00 00 40 00 00 02 6F 62
					39 00 00 40 00 00 06 BD 12 09 04 86 97 //Comp0_B_Gray0~4_DBV3
					15 00 00 40 00 00 02 6F 67
					39 00 00 00 00 00 06 BD 12 09 04 86 97 //Comp0_B_Gray0~4_DBV4
				];
				oplus,dsi-on-command = [
					// init code
					39 00 00 00 00 00 05 FF AA 55 A5 81
					39 00 00 00 00 00 02 6F 0C
					39 00 00 00 00 00 02 FD 08
					39 00 00 00 00 00 02 6F 02
					39 00 00 00 00 00 02 F9 84
					39 00 00 00 00 00 02 6F 10
					39 00 00 00 00 00 02 FB 40
					39 00 00 00 00 00 05 FF AA 55 A5 80
					39 00 00 00 00 00 02 6F 48
					39 00 00 00 00 00 02 F2 00
					39 00 00 00 00 00 05 FF AA 55 A5 80
					39 00 00 00 00 00 02 6F 16
					39 00 00 00 00 00 03 F4 02 74
					39 00 00 00 00 00 05 FF AA 55 A5 80
					39 00 00 00 00 00 02 6F 42
					39 00 00 00 00 00 02 F4 00
					39 00 00 00 00 00 05 FF AA 55 A5 80
					39 00 00 00 00 00 02 6F 49
					39 00 00 00 00 00 02 F2 10
					39 00 00 00 00 00 05 FF AA 55 A5 81
					39 00 00 00 00 00 02 6F 05
					39 00 00 00 00 00 03 FE 3C 3C
					39 00 00 00 00 00 05 FF AA 55 A5 82
					39 00 00 00 00 00 02 6F 09
					39 00 00 00 00 00 02 F2 FF
					39 00 00 00 00 00 05 FF AA 55 A5 80
					39 00 00 00 00 00 02 6F 04
					39 00 00 00 00 00 02 F2 3C
					39 00 00 00 00 00 05 FF AA 55 A5 80
					39 00 00 00 00 00 02 6F 0A
					39 00 00 00 00 00 06 F6 70 70 70 70 70 //Power seq
					39 00 00 00 00 00 05 FF AA 55 A5 81
					39 00 00 00 00 00 02 6F 0D
					39 00 00 00 00 00 02 FB 80 // TE_opt
					39 00 00 00 00 00 06 F0 55 AA 52 08 01
					39 00 00 00 00 00 02 E5 00
					39 00 00 00 00 00 05 FF AA 55 A5 80
					39 00 00 00 00 00 02 6F 15
					39 00 00 00 00 00 03 F8 01 8C // DSPOSC=138.6MHz
					39 00 00 00 00 00 05 FF AA 55 A5 80
					39 00 00 00 00 00 02 6F 3E
					39 00 00 00 00 00 02 F8 00
					39 00 00 00 00 00 05 FF AA 55 A5 81
					39 00 00 00 00 00 02 6F 0B
					39 00 00 00 00 00 02 FD 04
					39 00 00 00 00 00 02 5A 01
					39 00 00 00 00 00 02 17 30
					39 00 00 00 00 00 03 5F 00 00
					39 00 00 00 00 00 02 35 00 // TE on
					39 00 00 00 00 00 0A 88 01 02 5F 09 4F 00 00 00 00
					39 00 00 00 00 00 02 53 20
					39 00 00 00 00 00 05 2A 00 00 04 BF
					39 00 00 00 00 00 05 2B 00 00 0A 4F
					39 00 00 00 00 00 02 90 03
					39 00 00 00 00 00 02 6F 01
					39 00 00 00 00 00 02 90 43
					39 00 00 00 00 00 13 91 AB A8 00 14 C2 00 02 31 02 05 00 08 05 0E 04 7B 10 E0 // VESA
					39 00 00 00 00 00 02 26 00
					39 00 00 00 00 00 02 6D 00
					39 00 00 00 00 00 02 6F 06
					39 00 00 00 00 00 02 6D 00
					//Vporch Setting
					39 00 00 00 00 00 06 F0 55 AA 52 08 00
					39 00 00 00 00 00 08 BA 00 59 00 4C 00 64 10
					39 00 00 00 00 00 02 6F 07
					39 00 00 00 00 00 08 BA 00 59 00 4C 04 0C 10
					//Chopper Setting
					39 00 00 00 00 00 06 F0 55 AA 52 08 01
					39 00 00 00 00 00 05 D9 48 50 13 40
					39 00 00 00 00 00 02 6F 23
					39 00 00 00 00 00 04 D9 C1 49 13
					39 00 00 00 00 00 06 F0 55 AA 52 08 08 //alpha LUT
					39 00 00 00 00 00 02 6F 30
					39 00 00 00 00 00 15 B2 00 00 24 B8 2C A8 34 E8 3C 78 23 B7 29 D7 33 D7 3F 27 29 96
					39 00 00 00 00 00 02 6F 44
					39 00 00 00 00 00 15 B2 34 76 22 75 2A 65 32 95 21 E4 20 53 2C E3 2C C3 26 52 20 81
					39 00 00 00 00 00 02 6F 58
					39 00 00 00 00 00 0B B2 31 31 28 30 00 1F 00 1F 00 1F
					39 00 00 00 00 00 02 6F 00
					39 00 00 00 00 00 15 B2 00 01 00 38 00 6F 00 A6 00 DD 01 14 01 5E 01 82 01 B9 01 E0
					39 00 00 00 00 00 02 6F 14
					39 00 00 00 00 00 15 B2 02 27 02 5E 02 95 02 E4 03 E5 04 8A 04 8B 05 DC 07 50 08 FC
					39 00 00 00 00 00 02 6F 28
					39 00 00 00 00 00 09 B2 0B 17 0D BB 0F FE 0F FF
					//odc on/fix
					39 00 00 00 00 00 06 F0 55 AA 52 08 08
					39 00 00 00 00 00 05 E0 21 01 01 01
					15 00 00 00 00 00 02 6F 06
					39 00 00 00 00 00 08 E0 80 30 21 32 43 54 65
					15 00 00 00 00 00 02 6F 0D
					39 00 00 00 00 00 07 E0 76 87 98 99 99 09
					39 00 00 00 00 00 08 E1 00 00 00 00 00 00 00
					15 00 00 00 00 00 02 6F 07
					39 00 00 00 00 00 08 E1 00 00 00 00 00 00 00
					15 00 00 00 00 00 02 6F 0E
					39 00 00 00 00 00 08 E1 00 00 00 00 00 00 00
					15 00 00 00 00 00 02 6F 15
					39 00 00 00 00 00 08 E1 00 00 00 00 00 00 00
					15 00 00 00 00 00 02 6F 1C
					39 00 00 00 00 00 08 E1 00 00 00 00 00 00 00
					15 00 00 00 00 00 02 6F 23
					39 00 00 00 00 00 08 E1 00 00 00 00 00 00 00
					15 00 00 00 00 00 02 6F 2A
					39 00 00 00 00 00 08 E1 00 00 00 00 00 00 00
					15 00 00 00 00 00 02 6F 31
					39 00 00 00 00 00 08 E1 00 00 00 00 00 00 00
					15 00 00 00 00 00 02 6F 38
					39 00 00 00 00 00 08 E1 00 00 00 00 00 00 00
					15 00 00 00 00 00 02 6F 3F
					39 00 00 00 00 00 08 E1 00 00 00 00 00 00 00
					15 00 00 00 00 00 02 6F 46
					39 00 00 00 00 00 08 E1 00 00 00 00 00 00 00
					15 00 00 00 00 00 02 6F 4D
					39 00 00 00 00 00 08 E1 00 00 00 00 00 00 00
					15 00 00 00 00 00 02 6F 54
					39 00 00 00 00 00 08 E1 00 00 00 00 00 00 00
					15 00 00 00 00 00 02 6F 5B
					39 00 00 00 00 00 08 E1 00 00 00 00 00 00 00
					15 00 00 00 00 00 02 6F 62
					39 00 00 00 00 00 08 E1 00 00 00 00 00 00 00
					15 00 00 00 00 00 02 6F 69
					39 00 00 00 00 00 08 E1 00 00 00 00 00 00 00
					15 00 00 00 00 00 02 6F 70
					39 00 00 00 00 00 08 E1 00 00 00 00 00 00 00
					15 00 00 00 00 00 02 6F 77
					39 00 00 00 00 00 08 E1 00 00 00 00 00 00 00
					39 00 00 00 00 00 08 E2 00 00 00 00 00 00 00
					15 00 00 00 00 00 02 6F 07
					39 00 00 00 00 00 08 E2 00 00 00 00 00 00 00
					15 00 00 00 00 00 02 6F 0E
					39 00 00 00 00 00 08 E2 00 00 00 00 00 00 00
					15 00 00 00 00 00 02 6F 15
					39 00 00 00 00 00 08 E2 00 00 00 00 00 00 00
					15 00 00 00 00 00 02 6F 1C
					39 00 00 00 00 00 08 E2 00 00 00 00 00 00 00
					15 00 00 00 00 00 02 6F 23
					39 00 00 00 00 00 08 E2 00 00 00 00 00 00 00
					15 00 00 00 00 00 02 6F 2A
					39 00 00 00 00 00 08 E2 02 04 0A 07 08 08 08
					15 00 00 00 00 00 02 6F 31
					39 00 00 00 00 00 08 E2 02 04 0A 07 08 08 08
					15 00 00 00 00 00 02 6F 38
					39 00 00 00 00 00 08 E2 02 04 0A 07 08 08 08
					15 00 00 00 00 00 02 6F 3F
					39 00 00 00 00 00 08 E2 02 04 0A 07 08 08 08
					15 00 00 00 00 00 02 6F 46
					39 00 00 00 00 00 08 E2 00 00 06 01 03 06 08
					15 00 00 00 00 00 02 6F 4D
					39 00 00 00 00 00 08 E2 02 04 0A 07 08 08 08
					15 00 00 00 00 00 02 6F 54
					39 00 00 00 00 00 08 E2 06 06 06 06 06 06 06
					15 00 00 00 00 00 02 6F 5B
					39 00 00 00 00 00 08 E2 06 06 06 06 06 06 06
					15 00 00 00 00 00 02 6F 62
					39 00 00 00 00 00 08 E2 06 06 06 06 06 06 06
					15 00 00 00 00 00 02 6F 69
					39 00 00 00 00 00 08 E2 06 06 06 06 06 06 06
					15 00 00 00 00 00 02 6F 70
					39 00 00 00 00 00 08 E2 07 07 07 07 07 07 07
					15 00 00 00 00 00 02 6F 77
					39 00 00 00 00 00 08 E2 07 07 07 07 07 07 07
					39 00 00 00 00 00 08 E3 00 00 00 00 00 00 00
					15 00 00 00 00 00 02 6F 07
					39 00 00 00 00 00 08 E3 00 00 00 00 00 00 00
					15 00 00 00 00 00 02 6F 0E
					39 00 00 00 00 00 08 E3 00 00 00 00 00 00 00
					15 00 00 00 00 00 02 6F 15
					39 00 00 00 00 00 08 E3 00 00 00 00 00 00 00
					15 00 00 00 00 00 02 6F 1C
					39 00 00 00 00 00 08 E3 00 00 00 00 00 00 00
					15 00 00 00 00 00 02 6F 23
					39 00 00 00 00 00 08 E3 00 00 00 00 00 00 00
					15 00 00 00 00 00 02 6F 2A
					39 00 00 00 00 00 08 E3 00 00 00 00 00 00 00
					15 00 00 00 00 00 02 6F 31
					39 00 00 00 00 00 08 E3 00 00 00 00 00 00 00
					15 00 00 00 00 00 02 6F 38
					39 00 00 00 00 00 08 E3 00 00 00 00 00 00 00
					15 00 00 00 00 00 02 6F 3F
					39 00 00 00 00 00 08 E3 00 00 00 00 00 00 00
					15 00 00 00 00 00 02 6F 46
					39 00 00 00 00 00 08 E3 00 00 00 00 00 00 00
					15 00 00 00 00 00 02 6F 4D
					39 00 00 00 00 00 08 E3 00 00 00 00 00 00 00
					15 00 00 00 00 00 02 6F 54
					39 00 00 00 00 00 08 E3 00 00 00 00 00 00 00
					15 00 00 00 00 00 02 6F 5B
					39 00 00 00 00 00 08 E3 00 00 00 00 00 00 00
					15 00 00 00 00 00 02 6F 62
					39 00 00 00 00 00 08 E3 00 00 00 00 00 00 00
					15 00 00 00 00 00 02 6F 69
					39 00 00 00 00 00 08 E3 00 00 00 00 00 00 00
					15 00 00 00 00 00 02 6F 70
					39 00 00 00 00 00 08 E3 00 00 00 00 00 00 00
					15 00 00 00 00 00 02 6F 77
					39 00 00 00 00 00 08 E3 00 00 00 00 00 00 00
					39 00 00 00 00 00 08 EA 00 00 00 00 00 00 00
					15 00 00 00 00 00 02 6F 07
					39 00 00 00 00 00 08 EA 00 00 00 00 00 00 00
					15 00 00 00 00 00 02 6F 0E
					39 00 00 00 00 00 08 EA 00 00 00 00 00 00 00
					15 00 00 00 00 00 02 6F 15
					39 00 00 00 00 00 07 EA 00 00 00 00 00 00
					39 00 00 00 00 00 08 E4 00 00 00 00 00 00 00
					15 00 00 00 00 00 02 6F 07
					39 00 00 00 00 00 03 E4 00 00
					39 00 00 00 00 00 08 E5 00 00 00 00 00 00 00
					15 00 00 00 00 00 02 6F 07
					39 00 00 00 00 00 03 E5 00 00
					39 00 00 00 00 00 08 E6 00 00 00 00 00 00 00
					15 00 00 00 00 00 02 6F 07
					39 00 00 00 00 00 03 E6 00 00
					39 00 00 00 00 00 08 E8 11 90 00 00 00 20 00
					15 00 00 00 00 00 02 6F 07
					39 00 00 00 00 00 08 E8 68 6C 6C 70 70 74 74
					15 00 00 00 00 00 02 6F 0E
					39 00 00 00 00 00 08 E8 78 78 7D 7D A0 A0 A1
					15 00 00 00 00 00 02 6F 15
					39 00 00 00 00 00 08 E8 A1 A1 A1 98 98 99 99
					15 00 00 00 00 00 02 6F 1C
					39 00 00 00 00 00 08 E8 99 00 48 4D 4D 4E 4E
					15 00 00 00 00 00 02 6F 23
					39 00 00 00 00 00 08 E8 52 52 56 56 5A 5A 90
					15 00 00 00 00 00 02 6F 2A
					39 00 00 00 00 00 08 E8 90 90 90 90 90 8D 8D
					15 00 00 00 00 00 02 6F 31
					39 00 00 00 00 00 08 E8 89 89 89 00 A8 AA AA
					15 00 00 00 00 00 02 6F 38
					39 00 00 00 00 00 08 E8 AA AA AA AA AB AB AD
					15 00 00 00 00 00 02 6F 3F
					39 00 00 00 00 00 08 E8 AD B8 B8 B8 B8 B8 B8
					15 00 00 00 00 00 02 6F 46
					39 00 00 00 00 00 06 E8 B5 B5 B3 B3 B0
					// serinal number
					39 00 00 00 00 00 06 F0 55 AA 52 08 01
					39 00 00 00 00 00 08 D7 3B 1B 17 24 2F 00 62
					// corner improve
					39 00 00 00 00 00 06 F0 55 AA 52 08 07
					39 00 00 00 00 00 04 C0 07 01 F8
					15 00 00 00 00 00 02 6F 03
					39 00 00 00 00 00 05 C0 00 F0 00 00
					39 00 00 00 00 00 16 C1 3C 00 0C B1 07 39 13 26 3F E7 D0 00 00 00 00 00 00 00 00 00 00
					15 00 00 00 00 00 02 6F 15
					39 00 00 00 00 00 11 C1 83 00 00 2B 9A 9A 21 33 C0 79 2B 00 00 00 00 00
					15 00 00 00 00 00 02 6F 25
					39 00 00 00 00 00 08 C1 00 26 2B AA 22 26 00
					39 00 00 00 00 00 16 C2 3C 00 07 E9 0E 89 15 72 3F F3 84 4C 00 0B 18 A0 00 00 00 00 00
					15 00 00 00 00 00 02 6F 15
					39 00 00 00 00 00 11 C2 04 00 2C B9 AA 22 4F 33 C0 D3 8D 00 00 00 00 00
					15 00 00 00 00 00 02 6F 25
					39 00 00 00 00 00 08 C2 44 94 9A AA 22 29 00
					39 00 00 00 00 00 16 C3 3A 0F 0B 64 06 91 EE B4 00 13 8D 68 00 03 26 1C 7F FC 64 FA 44
					15 00 00 00 00 00 02 6F 15
					39 00 00 00 00 00 11 C3 89 44 94 BF 9A 97 21 33 0F 8A 2B E8 D2 00 00 00
					15 00 00 00 00 00 02 6F 25
					39 00 00 00 00 00 08 C3 00 26 2B 00 29 2D 00
					39 00 00 00 00 00 16 C4 32 0F 07 39 07 E9 F0 E2 00 02 E5 72 00 12 B9 8E 7F FC 76 CF F9
					15 00 00 00 00 00 02 6F 15
					39 00 00 00 00 00 11 C4 2D 44 0C 93 AA 22 4F 33 0F 2D 87 E8 45 00 00 00
					15 00 00 00 00 00 02 6F 25
					39 00 00 00 00 00 08 C4 44 94 99 00 29 2D 00
					39 00 00 00 00 00 16 C5 30 0F 0B D1 07 39 ED 86 3F F2 0E AA 3F F8 61 E2 00 02 02 30 E9
					15 00 00 00 00 00 02 6F 15
					39 00 00 00 00 00 11 C5 02 00 00 2B 00 2E B5 33 F0 79 D5 16 AD 00 00 00
					15 00 00 00 00 00 02 6F 25
					39 00 00 00 00 00 08 C5 44 94 9A 00 26 2D 00
					39 00 00 00 00 00 16 C6 20 0F 07 E9 07 39 F0 E2 3F F7 A8 42 3F F2 37 5E 00 02 33 22 99
					15 00 00 00 00 00 02 6F 15
					39 00 00 00 00 00 11 C6 2D 00 2C B3 00 00 2D 33 F0 D3 79 17 BB 00 00 00
					15 00 00 00 00 00 02 6F 25
					39 00 00 00 00 00 08 C6 00 00 00 00 00 00 00
					39 00 00 00 00 00 16 C7 2E 00 08 A1 07 39 0F CA 00 0A DD 90 3F F5 9E 10 00 00 00 00 00
					15 00 00 00 00 00 02 6F 15
					39 00 00 00 00 00 11 C7 89 44 94 BF 00 2E B7 33 30 89 D5 00 00 00 00 00
					15 00 00 00 00 00 02 6F 25
					39 00 00 00 00 00 08 C7 00 00 00 00 00 00 00
					39 00 00 00 00 00 16 C8 26 00 07 E9 0C B1 14 0A 00 00 00 00 3F E6 B0 00 00 00 00 00 00
					15 00 00 00 00 00 02 6F 15
					39 00 00 00 00 00 11 C8 27 44 0C 93 00 00 2D 33 30 2D 79 00 00 00 00 00
					15 00 00 00 00 00 02 6F 25
					39 00 00 00 00 00 08 C8 00 00 00 00 00 00 00
					39 00 00 00 00 00 16 C9 21 00 05 A4 05 59 00 00 3F FE 5E 98 3F FE 69 94 00 00 1E 2A 04
					15 00 00 00 00 00 02 6F 15
					39 00 00 00 00 00 11 C9 0A 22 3A 5F 00 28 4E 33 F0 DA DB 05 7E 00 00 00
					15 00 00 00 00 00 02 6F 25
					39 00 00 00 00 00 08 C9 00 00 00 00 00 00 00
					39 00 00 00 00 00 16 CA 2D 00 05 A4 05 59 00 00 3F FE 5E 98 00 00 00 00 00 00 00 00 00
					15 00 00 00 00 00 02 6F 15
					39 00 00 00 00 00 11 CA 1B 22 3A 5F 00 4F 75 33 C0 DA 25 00 00 00 00 00
					15 00 00 00 00 00 02 6F 25
					39 00 00 00 00 00 08 CA 00 00 00 00 00 00 00
					39 00 00 00 00 00 16 CB 2B 00 05 A4 05 59 00 00 00 00 00 00 00 00 00 00 7F FF E1 D5 FC
					15 00 00 00 00 00 02 6F 15
					39 00 00 00 00 00 11 CB 1B 22 60 85 00 4F 75 33 0F 26 25 FA 82 00 00 00
					15 00 00 00 00 00 02 6F 25
					39 00 00 00 00 00 08 CB 00 00 00 00 00 00 00
					39 00 00 00 00 00 16 CC 27 00 05 A4 05 59 00 00 00 00 00 00 3F FE 69 94 00 00 00 00 00
					15 00 00 00 00 00 02 6F 15
					39 00 00 00 00 00 11 CC 0A 22 60 85 00 28 4E 33 30 26 DB 00 00 00 00 00
					15 00 00 00 00 00 02 6F 25
					39 00 00 00 00 00 08 CC 00 00 00 00 00 00 00
					39 00 00 00 00 00 16 CD 21 00 27 10 27 10 00 00 3F E1 7B 80 3F E1 7B 80 00 05 F5 E1 00
					15 00 00 00 00 00 02 6F 15
					39 00 00 00 00 00 11 CD 1D 12 FA 5E 89 EB 4F 33 F0 9C 9C 27 10 00 00 00
					15 00 00 00 00 00 02 6F 25
					39 00 00 00 00 00 08 CD 00 00 00 00 00 00 00
					39 00 00 00 00 00 16 CE 27 00 27 10 27 10 00 00 00 00 00 00 3F E1 7B 80 00 00 00 00 00
					15 00 00 00 00 00 02 6F 15
					39 00 00 00 00 00 11 CE 1D 22 5F C3 89 EB 4F 33 30 64 9C 00 00 00 00 00
					15 00 00 00 00 00 02 6F 25
					39 00 00 00 00 00 08 CE 00 00 00 00 00 00 00
					39 00 00 00 00 00 16 CF 2D 00 27 10 27 10 00 00 3F E1 7B 80 00 00 00 00 00 00 00 00 00
					15 00 00 00 00 00 02 6F 15
					39 00 00 00 00 00 11 CF 46 12 FA 5E 99 50 B4 33 C0 9C 64 00 00 00 00 00
					15 00 00 00 00 00 02 6F 25
					39 00 00 00 00 00 08 CF 00 00 00 00 00 00 00
					39 00 00 00 00 00 16 D0 2B 00 27 10 27 10 00 00 00 00 00 00 00 00 00 00 7F FA 0A 1F 00
					15 00 00 00 00 00 02 6F 15
					39 00 00 00 00 00 11 D0 46 22 5F C3 99 50 B4 33 0F 64 64 D8 F0 00 00 00
					15 00 00 00 00 00 02 6F 25
					39 00 00 00 00 00 08 D0 00 00 00 00 00 00 00
					39 00 00 00 00 00 0F D1 7F FC 4B 9A 69 04 BF 7F FB 86 2B AD 04 BF
					15 00 00 00 00 00 02 6F 0E
					39 00 00 00 00 00 0F D1 00 00 00 00 00 04 C0 00 00 00 00 00 04 C0
					15 00 00 00 00 00 02 6F 1C
					39 00 00 00 00 00 0F D1 80 00 00 00 00 04 BF 80 00 00 00 00 04 BF
					15 00 00 00 00 00 02 6F 2A
					39 00 00 00 00 00 0C D1 00 02 11 8A 09 00 00 00 02 33 22
					39 00 00 00 00 00 12 D2 99 00 00 00 00 00 00 00 04 C0 7F FF E1 D5 FC 04 C0
					39 00 00 00 00 00 06 F0 55 AA 52 08 00
					15 00 00 00 00 00 02 6F 13
					39 00 00 00 00 00 19 DF 02 5E 09 4F 00 00 00 00 01 FA 08 EB 02 C3 09 B4 00 00 00 00 00 00 00 00
					//skip sequence
					39 00 00 00 00 00 06 F0 55 AA 52 08 00
					39 00 00 00 00 00 02 6F 1C
					39 00 00 00 00 00 11 BA 01 01 01 01 00 01 03 03 00 01 03 03 00 00 00 00
					39 00 00 00 00 00 02 6F 2C
					39 00 00 00 00 00 11 BA 01 01 01 01 00 01 03 0B 00 01 03 0B 00 00 00 00
					39 00 00 00 00 00 02 6F 3C
					39 00 00 00 00 00 11 BA 01 01 01 01 00 01 03 17 00 01 03 17 00 00 00 00
					39 00 00 00 00 00 02 6F 4C
					39 00 00 00 00 00 11 BA 01 01 01 01 00 01 03 77 00 01 03 77 00 00 00 00
					39 00 00 00 00 00 02 6F 5C
					39 00 00 00 00 00 11 BA 01 01 01 01 01 01 01 01 01 01 01 01 01 01 01 01
					39 00 00 00 00 00 02 6F 6C
					39 00 00 00 00 00 09 BA 00 00 00 00 00 00 00 00
					39 00 00 00 00 00 02 6F 74
					39 00 00 00 00 00 11 BA 00 01 02 03 05 0B 17 77 00 01 02 05 08 11 59 00
					39 00 00 00 00 00 02 6F 84
					39 00 00 00 00 00 11 BA 00 01 02 03 05 0B 17 77 00 01 02 05 08 11 59 00
					39 00 00 00 00 00 02 6F 94
					39 00 00 00 00 00 11 BA 00 00 00 00 00 00 00 00 00 00 00 00 00 00 00 00
					39 00 00 00 00 00 02 6F A4
					39 00 00 00 00 00 11 BA 01 01 01 01 00 00 00 02 00 00 00 03 00 00 00 00
					39 00 00 00 00 00 02 6F B4
					39 00 00 00 00 00 05 BA 94 FA A4 3A
					39 00 00 00 00 00 02 6F B8
					39 00 00 00 00 00 09 BA 00 00 00 00 11 11 11 11
					39 00 00 00 00 00 02 6F C0
					39 00 00 00 00 00 09 BA 10 00 00 00 11 11 11 11
					39 00 00 00 00 00 02 6F 08
					39 00 00 00 00 00 05 BB 01 00 00 00
					39 00 00 00 00 00 02 6F 0C
					39 00 00 00 00 00 05 BB 01 02 02 00
					39 00 00 00 00 00 02 6F 10
					39 00 00 00 00 00 05 BB 01 05 05 00
					39 00 00 00 00 00 02 6F 14
					39 00 00 00 00 00 05 BB 01 00 00 00
					39 00 00 00 00 00 02 6F 18
					39 00 00 00 00 00 06 BB 01 00 1D 1D 00
					39 00 00 00 00 00 02 6F 1D
					39 00 00 00 00 00 05 BB 01 01 01 00
					15 00 00 00 00 00 02 6F 1E
					15 00 00 00 00 00 02 B5 19 // AOD discharge on DVT OTP
					39 00 00 00 00 00 06 F0 55 AA 52 08 08
					15 00 00 00 00 00 02 6F AC
					39 00 00 00 00 00 05 BC 00 10 10 00 // OD beta3 off DVT OTP
					// VFP/VBP SOP/GOP ON
					39 00 00 00 00 00 06 F0 55 AA 52 08 00
					15 00 00 00 00 00 02 6F 0D
					15 00 00 00 00 00 02 C2 0F
					//OSC：121.9-121.2 MHz
					39 00 00 00 00 00 05 FF AA 55 A5 80
					15 00 00 00 00 00 02 6F 31
					39 00 00 00 00 00 03 F8 01 B7
					// LFCC fix
					39 00 00 00 00 00 06 F0 55 AA 52 08 00
					15 00 00 00 00 00 02 6F 08
					15 00 00 00 00 00 02 B2 C0
					39 00 00 00 00 00 06 F0 55 AA 52 08 09
					//Comp_DBVPNTS0~5 = 423h,424h,48Ah,48Bh,4F0h,4F1h
					15 00 00 00 00 00 02 6F 01
					39 00 00 00 00 00 0A BD 44 23 24 44 8A 8B 44 F0 F1
					// Fixed TE
					15 00 00 00 00 00 02 5A 00
					15 00 00 00 00 00 02 6F 03
					15 00 00 00 00 00 02 5A 00
					39 00 00 00 00 00 03 44 00 00
					15 00 00 00 00 00 02 6F 04
					39 00 00 00 00 00 0D 44 00 00 00 00 00 00 00 00 00 00 00 00
					39 00 00 00 00 00 06 F0 55 AA 52 08 00
					15 00 00 00 00 00 02 BE 47
					// TEST TE
					39 00 00 00 00 00 06 F0 55 AA 52 08 00
					15 00 00 00 00 00 02 6F 01
					15 00 00 00 00 00 02 BE 54
					//2F:30->6D:08 90Hz(Repeat 1 times) --> 90Hz
					39 00 00 00 00 00 06 F0 55 AA 52 08 00
					15 00 00 00 00 00 02 6F 03
					39 00 00 00 00 00 03 35 00 00
					15 00 00 00 00 00 02 6F 20
					39 00 00 00 00 00 09 BA 00 01 02 02 00 01 02 02
					15 00 00 00 00 00 02 6F 30
					39 00 00 00 00 00 09 BA 00 01 02 08 00 01 02 08
					15 00 00 00 00 00 02 6F 40
					39 00 00 00 00 00 09 BA 00 01 02 11 00 01 02 11
					15 00 00 00 00 00 02 6F 50
					39 00 00 00 00 00 09 BA 00 01 02 59 00 01 02 59
					15 00 00 00 00 00 02 2F 31
					15 00 00 00 00 00 02 6D 08 //90Hz
					// DC/PWM fix
					39 00 00 00 00 00 06 F0 55 AA 52 08 09
					15 00 00 00 00 00 02 6F 1C
					39 00 00 00 00 00 06 BD 98 89 84 02 15 //Comp0_R_Gray0~4_DBV1
					15 00 00 00 00 00 02 6F 21
					39 00 00 00 00 00 06 BD 98 89 84 02 15 //Comp0_R_Gray0~4_DBV2
					15 00 00 00 00 00 02 6F 26
					39 00 00 00 00 00 06 BD 12 09 04 86 97 //Comp0_R_Gray0~4_DBV3
					15 00 00 00 00 00 02 6F 2B
					39 00 00 00 00 00 06 BD 12 09 04 86 97 //Comp0_R_Gray0~4_DBV4
					15 00 00 00 00 00 02 6F 3A
					39 00 00 00 00 00 06 BD 98 89 84 02 15 //Comp0_G_Gray0~4_DBV1
					15 00 00 00 00 00 02 6F 3F
					39 00 00 00 00 00 06 BD 98 89 84 02 15 //Comp0_G_Gray0~4_DBV1
					15 00 00 00 00 00 02 6F 44
					39 00 00 00 00 00 06 BD 12 09 04 86 97 //Comp0_G_Gray0~4_DBV3
					15 00 00 00 00 00 02 6F 49
					39 00 00 00 00 00 06 BD 12 09 04 86 97 //Comp0_G_Gray0~4_DBV4
					15 00 00 00 00 00 02 6F 58
					39 00 00 00 00 00 06 BD 98 09 84 02 15 //Comp 0_B_Gray0~4_DBV1
					15 00 00 00 00 00 02 6F 5D
					39 00 00 00 00 00 06 BD 98 89 84 02 15 //Comp0_B_Gray0~4_DBV1
					15 00 00 00 00 00 02 6F 62
					39 00 00 00 00 00 06 BD 12 09 04 86 97 //Comp0_B_Gray0~4_DBV3
					15 00 00 00 00 00 02 6F 67
					39 00 00 00 00 00 06 BD 12 09 04 86 97 //Comp0_B_Gray0~4_DBV4
					//osc fixed
					39 00 00 00 00 00 06 F0 55 AA 52 08 01
					39 00 00 00 00 00 06 C3 DD 06 20 11 FF
					15 00 00 00 00 00 02 6F 05
					39 00 00 00 00 00 06 C3 00 06 20 11 FF
					15 00 00 00 00 00 02 6F 0A
					39 00 00 00 00 00 06 C3 00 07 0E 20 06
					15 00 00 00 00 00 02 6F 0F
					39 00 00 00 00 00 06 C3 44 19 07 11 18
					15 00 00 00 00 00 02 6F 14
					39 00 00 00 00 00 06 C3 06 5C 13 07 0E
					15 00 00 00 00 00 02 6F 19
					39 00 00 00 00 00 06 C3 20 06 44 19 07
					15 00 00 00 00 00 02 6F 1E
					39 00 00 00 00 00 06 C3 0E 20 06 44 19
					15 00 00 00 00 00 02 6F 23
					39 00 00 00 00 00 06 C3 07 0E 20 06 44
					15 00 00 00 00 00 02 6F 28
					15 00 00 00 00 00 02 C3 19
					//Modify power-off timing
					39 00 00 00 00 00 06 F0 55 AA 52 08 03
					15 00 00 00 00 00 02 6F 07
					15 00 00 00 00 00 02 C6 48
					//Light On
					39 00 00 00 78 00 01 11 // Sleep out
					39 00 00 00 00 00 01 29 // Display out
				];
					oplus,dsi-aod-off-command = [
					39 00 00 40 00 00 06 F0 55 AA 52 08 00
					39 00 00 40 00 00 02 2F 31
					39 00 00 40 00 00 02 6F 03
					39 00 00 40 00 00 03 35 00 00
					39 00 00 40 00 00 02 38 00
					05 00 00 40 00 00 01 2C
					39 00 00 40 00 00 03 51 00 00
					39 00 00 40 00 00 06 F0 55 AA 52 08 08
					39 00 00 40 00 00 02 BE 03
					39 00 00 40 00 00 05 FF AA 55 A5 81
					39 00 00 40 00 00 02 6F 0B
					39 00 00 00 00 00 02 FD 04 //gmaconv on
				];
				oplus,dsi-panel-aod-off-insert-black-command = [
					39 00 00 40 00 00 06 F0 55 AA 52 08 00
					39 00 00 40 00 00 02 C0 66
					39 00 00 40 00 00 06 F0 55 AA 52 08 01
					39 00 00 40 00 00 06 D2 00 11 00 00 15
					39 00 00 40 00 00 02 2F 31
					39 00 00 40 00 00 02 6F 03
					39 00 00 40 00 00 03 35 00 00
					39 00 00 40 00 00 02 38 00
					39 00 00 00 00 00 03 51 00 00
				];
				oplus,dsi-ultra-low-power-aod-on-command = [
					39 00 00 40 00 00 06 F0 55 AA 52 08 00
					39 00 00 40 00 00 02 6F 18
					39 00 00 00 00 00 06 BB 01 00 02 02 00
				];
				oplus,dsi-ultra-low-power-aod-off-command = [
					39 00 00 40 00 00 06 F0 55 AA 52 08 00
					39 00 00 40 00 00 02 6F 18
					39 00 00 00 00 00 06 BB 01 00 00 00 00
				];
				oplus,dsi-hbm-on-command = [
					39 00 00 00 00 00 03 51 0F FE
				];
				oplus,dsi-hbm-off-command = [
					39 00 00 00 00 00 03 51 0D BB
				];
				oplus,dsi-adfr-min-fps-90hz-command = [
					39 00 00 40 00 00 06 F0 55 AA 52 08 09
					15 00 00 40 00 00 02 6F 1C
					39 00 00 40 00 00 06 BD 98 89 84 02 15
					15 00 00 40 00 00 02 6F 21
					39 00 00 40 00 00 06 BD 98 89 84 02 15
					15 00 00 40 00 00 02 6F 26
					39 00 00 40 00 00 06 BD 12 09 04 86 97
					15 00 00 40 00 00 02 6F 2B
					39 00 00 40 00 00 06 BD 12 09 04 86 97
					15 00 00 40 00 00 02 6F 3A
					39 00 00 40 00 00 06 BD 98 89 84 02 15
					15 00 00 40 00 00 02 6F 3F
					39 00 00 40 00 00 06 BD 98 89 84 02 15
					15 00 00 40 00 00 02 6F 44
					39 00 00 40 00 00 06 BD 12 09 04 86 97
					15 00 00 40 00 00 02 6F 49
					39 00 00 40 00 00 06 BD 12 09 04 86 97
					15 00 00 40 00 00 02 6F 58
					39 00 00 40 00 00 06 BD 98 89 84 02 15
					15 00 00 40 00 00 02 6F 5D
					39 00 00 40 00 00 06 BD 98 89 84 02 15
					15 00 00 40 00 00 02 6F 62
					39 00 00 40 00 00 06 BD 12 09 04 86 97
					15 00 00 40 00 00 02 6F 67
					39 00 00 40 00 00 06 BD 12 09 04 86 97
					39 00 00 40 00 00 02 2F 31
					39 00 00 00 00 00 02 6D 08
				];
				oplus,dsi-adfr-min-fps-30hz-command = [
					39 00 00 40 00 00 06 F0 55 AA 52 08 09
					15 00 00 40 00 00 02 6F 1C
					39 00 00 40 00 00 06 BD 98 89 84 02 15
					15 00 00 40 00 00 02 6F 21
					39 00 00 40 00 00 06 BD 98 89 84 02 15
					15 00 00 40 00 00 02 6F 26
					39 00 00 40 00 00 06 BD 12 09 04 86 97
					15 00 00 40 00 00 02 6F 2B
					39 00 00 40 00 00 06 BD 12 09 04 86 97
					15 00 00 40 00 00 02 6F 3A
					39 00 00 40 00 00 06 BD 98 89 84 02 15
					15 00 00 40 00 00 02 6F 3F
					39 00 00 40 00 00 06 BD 98 89 84 02 15
					15 00 00 40 00 00 02 6F 44
					39 00 00 40 00 00 06 BD 12 09 04 86 97
					15 00 00 40 00 00 02 6F 49
					39 00 00 40 00 00 06 BD 12 09 04 86 97
					15 00 00 40 00 00 02 6F 58
					39 00 00 40 00 00 06 BD 98 89 84 02 15
					15 00 00 40 00 00 02 6F 5D
					39 00 00 40 00 00 06 BD 98 89 84 02 15
					15 00 00 40 00 00 02 6F 62
					39 00 00 40 00 00 06 BD 12 09 04 86 97
					15 00 00 40 00 00 02 6F 67
					39 00 00 40 00 00 06 BD 12 09 04 86 97
					39 00 00 40 00 00 02 2F 31
					39 00 00 00 00 00 02 6D 0A
				];
				oplus,dsi-adfr-min-fps-10hz-command = [
					39 00 00 40 00 00 06 F0 55 AA 52 08 09
					15 00 00 40 00 00 02 6F 1C
					39 00 00 40 00 00 06 BD 98 89 84 02 15
					15 00 00 40 00 00 02 6F 21
					39 00 00 40 00 00 06 BD 98 89 84 02 15
					15 00 00 40 00 00 02 6F 26
					39 00 00 40 00 00 06 BD 12 09 04 86 97
					15 00 00 40 00 00 02 6F 2B
					39 00 00 40 00 00 06 BD 12 09 04 86 97
					15 00 00 40 00 00 02 6F 3A
					39 00 00 40 00 00 06 BD 98 89 84 02 15
					15 00 00 40 00 00 02 6F 3F
					39 00 00 40 00 00 06 BD 98 89 84 02 15
					15 00 00 40 00 00 02 6F 44
					39 00 00 40 00 00 06 BD 12 09 04 86 97
					15 00 00 40 00 00 02 6F 49
					39 00 00 40 00 00 06 BD 12 09 04 86 97
					15 00 00 40 00 00 02 6F 58
					39 00 00 40 00 00 06 BD 98 89 84 02 15
					15 00 00 40 00 00 02 6F 5D
					39 00 00 40 00 00 06 BD 98 89 84 02 15
					15 00 00 40 00 00 02 6F 62
					39 00 00 40 00 00 06 BD 12 09 04 86 97
					15 00 00 40 00 00 02 6F 67
					39 00 00 40 00 00 06 BD 12 09 04 86 97
					39 00 00 40 00 00 02 2F 31
					39 00 00 00 00 00 02 6D 0C
				];
				oplus,dsi-adfr-min-fps-1hz-command = [
					39 00 00 40 00 00 06 F0 55 AA 52 08 09
					15 00 00 40 00 00 02 6F 1C
					39 00 00 40 00 00 06 BD 98 89 84 02 15
					15 00 00 40 00 00 02 6F 21
					39 00 00 40 00 00 06 BD 98 89 84 02 15
					15 00 00 40 00 00 02 6F 26
					39 00 00 40 00 00 06 BD 12 09 04 86 97
					15 00 00 40 00 00 02 6F 2B
					39 00 00 40 00 00 06 BD 12 09 04 86 97
					15 00 00 40 00 00 02 6F 3A
					39 00 00 40 00 00 06 BD 98 89 84 02 15
					15 00 00 40 00 00 02 6F 3F
					39 00 00 40 00 00 06 BD 98 89 84 02 15
					15 00 00 40 00 00 02 6F 44
					39 00 00 40 00 00 06 BD 12 09 04 86 97
					15 00 00 40 00 00 02 6F 49
					39 00 00 40 00 00 06 BD 12 09 04 86 97
					15 00 00 40 00 00 02 6F 58
					39 00 00 40 00 00 06 BD 98 89 84 02 15
					15 00 00 40 00 00 02 6F 5D
					39 00 00 40 00 00 06 BD 98 89 84 02 15
					15 00 00 40 00 00 02 6F 62
					39 00 00 40 00 00 06 BD 12 09 04 86 97
					15 00 00 40 00 00 02 6F 67
					39 00 00 40 00 00 06 BD 12 09 04 86 97
					39 00 00 40 00 00 02 2F 31
					39 00 00 00 00 00 02 6D 0E
				];
				oplus,dsi-timing-switch-command-state = "dsi_hs_mode";
				oplus,dsi-on-command-state = "dsi_lp_mode";
				oplus,dsi-aod-off-command-state = "dsi_ls_mode";
				oplus,dsi-panel-aod-off-insert-black-command-state = "dsi_ls_mode";
				oplus,dsi-ultra-low-power-aod-on-command-state = "dsi_ls_mode";
				oplus,dsi-ultra-low-power-aod-off-command-state = "dsi_ls_mode";
				oplus,dsi-hbm-on-command-state = "dsi_hs_mode";
				oplus,dsi-hbm-off-command-state = "dsi_hs_mode";
				oplus,dsi-adfr-min-fps-90hz-command-state = "dsi_hs_mode";
				oplus,dsi-adfr-min-fps-30hz-command-state = "dsi_hs_mode";
				oplus,dsi-adfr-min-fps-10hz-command-state = "dsi_hs_mode";
				oplus,dsi-adfr-min-fps-1hz-command-state = "dsi_hs_mode";
				oplus,dsc-params-entries = <&dsc_params>;
				oplus,spr-params-entries = <&spr_params>;
				oplus,dyn-fps {
					switch_en = <1>;
					vact_timing_fps = <90>;
					apollo_limit_superior_us = <7880>;
					apollo_limit_inferior_us = <10000>;
					apollo_transfer_time_us = <8800>;
				};
				oplus,display-mode {
					display-mode@0 {
						hdisplay = <1216>;
						vdisplay = <2640>;
						fhd-hfp = <2>;
						fhd-hsa = <26>;
						fhd-hbp = <36>;
						fhd-vfp = <100>;
						fhd-vsa = <8>;
						fhd-vbp = <76>;
						hskew = <STANDARD_ADFR>;
					};
					display-mode@1 {
						hdisplay = <1080>;
						vdisplay = <2344>;
						fhd-hfp = <2>;
						fhd-hsa = <26>;
						fhd-hbp = <36>;
						fhd-vfp = <100>;
						fhd-vsa = <8>;
						fhd-vbp = <76>;
						hskew = <STANDARD_ADFR>;
					};
				};
			};
			timing@sa_fhd_120 {
				cell-index = <2>;
				oplus,dsi-panel-framerate = <120>;
				oplus,dsi-panel-pllclk = <553>;
				oplus,cmd-null-pkt-en = <0>;
				oplus,cmd-null-pkt-len = <0>;
				oplus,merge-trig-offset = <333>;
				oplus,ofp-aod-off-setbacklight-delay = <4>;
				#include "panel-ac247-p-7-a0014-dsi-cmd-common-T0.dtsi"
				oplus,dsi-timing-switch-command = [
					//120HZ
					39 00 00 40 00 00 06 F0 55 AA 52 08 00
					15 00 00 40 00 00 02 6F 03
					39 00 00 40 00 00 03 35 00 00
					15 00 00 40 00 00 02 6F 20
					39 00 00 40 00 00 09 BA 00 01 03 03 00 01 03 03
					15 00 00 40 00 00 02 6F 30
					39 00 00 40 00 00 09 BA 00 01 03 0B 00 01 03 0B
					15 00 00 40 00 00 02 6F 40
					39 00 00 40 00 00 09 BA 00 01 03 17 00 01 03 17
					15 00 00 40 00 00 02 6F 50
					39 00 00 40 00 00 09 BA 00 01 03 77 00 01 03 77
					15 00 00 40 00 00 02 2F 30
					15 00 00 40 00 00 02 6D 00 //120Hz
					// DC/PWM fix
					39 00 00 40 00 00 06 F0 55 AA 52 08 09
					15 00 00 40 00 00 02 6F 1C
					39 00 00 40 00 00 06 BD A0 89 84 02 15 //Comp0_R_Gray0~4_DBV1
					15 00 00 40 00 00 02 6F 21
					39 00 00 40 00 00 06 BD A0 89 84 02 15 //Comp0_R_Gray0~4_DBV2
					15 00 00 40 00 00 02 6F 26
					39 00 00 40 00 00 06 BD 14 09 04 86 97 //Comp0_R_Gray0~4_DBV3
					15 00 00 40 00 00 02 6F 2B
					39 00 00 40 00 00 06 BD 14 09 04 86 97 //Comp0_R_Gray0~4_DBV4
					15 00 00 40 00 00 02 6F 3A
					39 00 00 40 00 00 06 BD A0 89 84 02 15 //Comp0_G_Gray0~4_DBV1
					15 00 00 40 00 00 02 6F 3F
					39 00 00 40 00 00 06 BD A0 89 84 02 15 //Comp0_G_Gray0~4_DBV1
					15 00 00 40 00 00 02 6F 44
					39 00 00 40 00 00 06 BD 14 09 04 86 97 //Comp0_G_Gray0~4_DBV3
					15 00 00 40 00 00 02 6F 49
					39 00 00 40 00 00 06 BD 14 09 04 86 97 //Comp0_G_Gray0~4_DBV4
					15 00 00 40 00 00 02 6F 58
					39 00 00 40 00 00 06 BD A0 89 84 02 15 //Comp0_B_Gray0~4_DBV1
					15 00 00 40 00 00 02 6F 5D
					39 00 00 40 00 00 06 BD A0 89 84 02 15 //Comp0_B_Gray0~4_DBV1
					15 00 00 40 00 00 02 6F 62
					39 00 00 40 00 00 06 BD 14 09 04 86 97 //Comp0_B_Gray0~4_DBV3
					15 00 00 40 00 00 02 6F 67
					39 00 00 00 00 00 06 BD 14 09 04 86 97 //Comp0_B_Gray0~4_DBV4
				];
				oplus,dsi-on-command = [
					// init code
					39 00 00 00 00 00 05 FF AA 55 A5 81
					39 00 00 00 00 00 02 6F 0C
					39 00 00 00 00 00 02 FD 08
					39 00 00 00 00 00 02 6F 02
					39 00 00 00 00 00 02 F9 84
					39 00 00 00 00 00 02 6F 10
					39 00 00 00 00 00 02 FB 40
					39 00 00 00 00 00 05 FF AA 55 A5 80
					39 00 00 00 00 00 02 6F 48
					39 00 00 00 00 00 02 F2 00
					39 00 00 00 00 00 05 FF AA 55 A5 80
					39 00 00 00 00 00 02 6F 16
					39 00 00 00 00 00 03 F4 02 74
					39 00 00 00 00 00 05 FF AA 55 A5 80
					39 00 00 00 00 00 02 6F 42
					39 00 00 00 00 00 02 F4 00
					39 00 00 00 00 00 05 FF AA 55 A5 80
					39 00 00 00 00 00 02 6F 49
					39 00 00 00 00 00 02 F2 10
					39 00 00 00 00 00 05 FF AA 55 A5 81
					39 00 00 00 00 00 02 6F 05
					39 00 00 00 00 00 03 FE 3C 3C
					39 00 00 00 00 00 05 FF AA 55 A5 82
					39 00 00 00 00 00 02 6F 09
					39 00 00 00 00 00 02 F2 FF
					39 00 00 00 00 00 05 FF AA 55 A5 80
					39 00 00 00 00 00 02 6F 04
					39 00 00 00 00 00 02 F2 3C
					39 00 00 00 00 00 05 FF AA 55 A5 80
					39 00 00 00 00 00 02 6F 0A
					39 00 00 00 00 00 06 F6 70 70 70 70 70 //Power seq
					39 00 00 00 00 00 05 FF AA 55 A5 81
					39 00 00 00 00 00 02 6F 0D
					39 00 00 00 00 00 02 FB 80 // TE_opt
					39 00 00 00 00 00 06 F0 55 AA 52 08 01
					39 00 00 00 00 00 02 E5 00
					39 00 00 00 00 00 05 FF AA 55 A5 80
					39 00 00 00 00 00 02 6F 15
					39 00 00 00 00 00 03 F8 01 8C // DSPOSC=138.6MHz
					39 00 00 00 00 00 05 FF AA 55 A5 80
					39 00 00 00 00 00 02 6F 3E
					39 00 00 00 00 00 02 F8 00
					39 00 00 00 00 00 05 FF AA 55 A5 81
					39 00 00 00 00 00 02 6F 0B
					39 00 00 00 00 00 02 FD 04
					39 00 00 00 00 00 02 5A 01
					39 00 00 00 00 00 02 17 30
					39 00 00 00 00 00 03 5F 00 00
					39 00 00 00 00 00 02 35 00 // TE on
					39 00 00 00 00 00 0A 88 01 02 5F 09 4F 00 00 00 00
					39 00 00 00 00 00 02 53 20
					39 00 00 00 00 00 05 2A 00 00 04 BF
					39 00 00 00 00 00 05 2B 00 00 0A 4F
					39 00 00 00 00 00 02 90 03
					39 00 00 00 00 00 02 6F 01
					39 00 00 00 00 00 02 90 43
					39 00 00 00 00 00 13 91 AB A8 00 14 C2 00 02 31 02 05 00 08 05 0E 04 7B 10 E0 // VESA
					39 00 00 00 00 00 02 26 00
					39 00 00 00 00 00 02 6D 00
					39 00 00 00 00 00 02 6F 06
					39 00 00 00 00 00 02 6D 00
					//Vporch Setting
					39 00 00 00 00 00 06 F0 55 AA 52 08 00
					39 00 00 00 00 00 08 BA 00 59 00 4C 00 64 10
					39 00 00 00 00 00 02 6F 07
					39 00 00 00 00 00 08 BA 00 59 00 4C 04 0C 10
					//Chopper Setting
					39 00 00 00 00 00 06 F0 55 AA 52 08 01
					39 00 00 00 00 00 05 D9 48 50 13 40
					39 00 00 00 00 00 02 6F 23
					39 00 00 00 00 00 04 D9 C1 49 13
					39 00 00 00 00 00 06 F0 55 AA 52 08 08 //alpha LUT
					39 00 00 00 00 00 02 6F 30
					39 00 00 00 00 00 15 B2 00 00 24 B8 2C A8 34 E8 3C 78 23 B7 29 D7 33 D7 3F 27 29 96
					39 00 00 00 00 00 02 6F 44
					39 00 00 00 00 00 15 B2 34 76 22 75 2A 65 32 95 21 E4 20 53 2C E3 2C C3 26 52 20 81
					39 00 00 00 00 00 02 6F 58
					39 00 00 00 00 00 0B B2 31 31 28 30 00 1F 00 1F 00 1F
					39 00 00 00 00 00 02 6F 00
					39 00 00 00 00 00 15 B2 00 01 00 38 00 6F 00 A6 00 DD 01 14 01 5E 01 82 01 B9 01 E0
					39 00 00 00 00 00 02 6F 14
					39 00 00 00 00 00 15 B2 02 27 02 5E 02 95 02 E4 03 E5 04 8A 04 8B 05 DC 07 50 08 FC
					39 00 00 00 00 00 02 6F 28
					39 00 00 00 00 00 09 B2 0B 17 0D BB 0F FE 0F FF
					//odc on/fix
					39 00 00 00 00 00 06 F0 55 AA 52 08 08
					39 00 00 00 00 00 05 E0 21 01 01 01
					15 00 00 00 00 00 02 6F 06
					39 00 00 00 00 00 08 E0 80 30 21 32 43 54 65
					15 00 00 00 00 00 02 6F 0D
					39 00 00 00 00 00 07 E0 76 87 98 99 99 09
					39 00 00 00 00 00 08 E1 00 00 00 00 00 00 00
					15 00 00 00 00 00 02 6F 07
					39 00 00 00 00 00 08 E1 00 00 00 00 00 00 00
					15 00 00 00 00 00 02 6F 0E
					39 00 00 00 00 00 08 E1 00 00 00 00 00 00 00
					15 00 00 00 00 00 02 6F 15
					39 00 00 00 00 00 08 E1 00 00 00 00 00 00 00
					15 00 00 00 00 00 02 6F 1C
					39 00 00 00 00 00 08 E1 00 00 00 00 00 00 00
					15 00 00 00 00 00 02 6F 23
					39 00 00 00 00 00 08 E1 00 00 00 00 00 00 00
					15 00 00 00 00 00 02 6F 2A
					39 00 00 00 00 00 08 E1 00 00 00 00 00 00 00
					15 00 00 00 00 00 02 6F 31
					39 00 00 00 00 00 08 E1 00 00 00 00 00 00 00
					15 00 00 00 00 00 02 6F 38
					39 00 00 00 00 00 08 E1 00 00 00 00 00 00 00
					15 00 00 00 00 00 02 6F 3F
					39 00 00 00 00 00 08 E1 00 00 00 00 00 00 00
					15 00 00 00 00 00 02 6F 46
					39 00 00 00 00 00 08 E1 00 00 00 00 00 00 00
					15 00 00 00 00 00 02 6F 4D
					39 00 00 00 00 00 08 E1 00 00 00 00 00 00 00
					15 00 00 00 00 00 02 6F 54
					39 00 00 00 00 00 08 E1 00 00 00 00 00 00 00
					15 00 00 00 00 00 02 6F 5B
					39 00 00 00 00 00 08 E1 00 00 00 00 00 00 00
					15 00 00 00 00 00 02 6F 62
					39 00 00 00 00 00 08 E1 00 00 00 00 00 00 00
					15 00 00 00 00 00 02 6F 69
					39 00 00 00 00 00 08 E1 00 00 00 00 00 00 00
					15 00 00 00 00 00 02 6F 70
					39 00 00 00 00 00 08 E1 00 00 00 00 00 00 00
					15 00 00 00 00 00 02 6F 77
					39 00 00 00 00 00 08 E1 00 00 00 00 00 00 00
					39 00 00 00 00 00 08 E2 00 00 00 00 00 00 00
					15 00 00 00 00 00 02 6F 07
					39 00 00 00 00 00 08 E2 00 00 00 00 00 00 00
					15 00 00 00 00 00 02 6F 0E
					39 00 00 00 00 00 08 E2 00 00 00 00 00 00 00
					15 00 00 00 00 00 02 6F 15
					39 00 00 00 00 00 08 E2 00 00 00 00 00 00 00
					15 00 00 00 00 00 02 6F 1C
					39 00 00 00 00 00 08 E2 00 00 00 00 00 00 00
					15 00 00 00 00 00 02 6F 23
					39 00 00 00 00 00 08 E2 00 00 00 00 00 00 00
					15 00 00 00 00 00 02 6F 2A
					39 00 00 00 00 00 08 E2 02 04 0A 07 08 08 08
					15 00 00 00 00 00 02 6F 31
					39 00 00 00 00 00 08 E2 02 04 0A 07 08 08 08
					15 00 00 00 00 00 02 6F 38
					39 00 00 00 00 00 08 E2 02 04 0A 07 08 08 08
					15 00 00 00 00 00 02 6F 3F
					39 00 00 00 00 00 08 E2 02 04 0A 07 08 08 08
					15 00 00 00 00 00 02 6F 46
					39 00 00 00 00 00 08 E2 00 00 06 01 03 06 08
					15 00 00 00 00 00 02 6F 4D
					39 00 00 00 00 00 08 E2 02 04 0A 07 08 08 08
					15 00 00 00 00 00 02 6F 54
					39 00 00 00 00 00 08 E2 06 06 06 06 06 06 06
					15 00 00 00 00 00 02 6F 5B
					39 00 00 00 00 00 08 E2 06 06 06 06 06 06 06
					15 00 00 00 00 00 02 6F 62
					39 00 00 00 00 00 08 E2 06 06 06 06 06 06 06
					15 00 00 00 00 00 02 6F 69
					39 00 00 00 00 00 08 E2 06 06 06 06 06 06 06
					15 00 00 00 00 00 02 6F 70
					39 00 00 00 00 00 08 E2 07 07 07 07 07 07 07
					15 00 00 00 00 00 02 6F 77
					39 00 00 00 00 00 08 E2 07 07 07 07 07 07 07
					39 00 00 00 00 00 08 E3 00 00 00 00 00 00 00
					15 00 00 00 00 00 02 6F 07
					39 00 00 00 00 00 08 E3 00 00 00 00 00 00 00
					15 00 00 00 00 00 02 6F 0E
					39 00 00 00 00 00 08 E3 00 00 00 00 00 00 00
					15 00 00 00 00 00 02 6F 15
					39 00 00 00 00 00 08 E3 00 00 00 00 00 00 00
					15 00 00 00 00 00 02 6F 1C
					39 00 00 00 00 00 08 E3 00 00 00 00 00 00 00
					15 00 00 00 00 00 02 6F 23
					39 00 00 00 00 00 08 E3 00 00 00 00 00 00 00
					15 00 00 00 00 00 02 6F 2A
					39 00 00 00 00 00 08 E3 00 00 00 00 00 00 00
					15 00 00 00 00 00 02 6F 31
					39 00 00 00 00 00 08 E3 00 00 00 00 00 00 00
					15 00 00 00 00 00 02 6F 38
					39 00 00 00 00 00 08 E3 00 00 00 00 00 00 00
					15 00 00 00 00 00 02 6F 3F
					39 00 00 00 00 00 08 E3 00 00 00 00 00 00 00
					15 00 00 00 00 00 02 6F 46
					39 00 00 00 00 00 08 E3 00 00 00 00 00 00 00
					15 00 00 00 00 00 02 6F 4D
					39 00 00 00 00 00 08 E3 00 00 00 00 00 00 00
					15 00 00 00 00 00 02 6F 54
					39 00 00 00 00 00 08 E3 00 00 00 00 00 00 00
					15 00 00 00 00 00 02 6F 5B
					39 00 00 00 00 00 08 E3 00 00 00 00 00 00 00
					15 00 00 00 00 00 02 6F 62
					39 00 00 00 00 00 08 E3 00 00 00 00 00 00 00
					15 00 00 00 00 00 02 6F 69
					39 00 00 00 00 00 08 E3 00 00 00 00 00 00 00
					15 00 00 00 00 00 02 6F 70
					39 00 00 00 00 00 08 E3 00 00 00 00 00 00 00
					15 00 00 00 00 00 02 6F 77
					39 00 00 00 00 00 08 E3 00 00 00 00 00 00 00
					39 00 00 00 00 00 08 EA 00 00 00 00 00 00 00
					15 00 00 00 00 00 02 6F 07
					39 00 00 00 00 00 08 EA 00 00 00 00 00 00 00
					15 00 00 00 00 00 02 6F 0E
					39 00 00 00 00 00 08 EA 00 00 00 00 00 00 00
					15 00 00 00 00 00 02 6F 15
					39 00 00 00 00 00 07 EA 00 00 00 00 00 00
					39 00 00 00 00 00 08 E4 00 00 00 00 00 00 00
					15 00 00 00 00 00 02 6F 07
					39 00 00 00 00 00 03 E4 00 00
					39 00 00 00 00 00 08 E5 00 00 00 00 00 00 00
					15 00 00 00 00 00 02 6F 07
					39 00 00 00 00 00 03 E5 00 00
					39 00 00 00 00 00 08 E6 00 00 00 00 00 00 00
					15 00 00 00 00 00 02 6F 07
					39 00 00 00 00 00 03 E6 00 00
					39 00 00 00 00 00 08 E8 11 90 00 00 00 20 00
					15 00 00 00 00 00 02 6F 07
					39 00 00 00 00 00 08 E8 68 6C 6C 70 70 74 74
					15 00 00 00 00 00 02 6F 0E
					39 00 00 00 00 00 08 E8 78 78 7D 7D A0 A0 A1
					15 00 00 00 00 00 02 6F 15
					39 00 00 00 00 00 08 E8 A1 A1 A1 98 98 99 99
					15 00 00 00 00 00 02 6F 1C
					39 00 00 00 00 00 08 E8 99 00 48 4D 4D 4E 4E
					15 00 00 00 00 00 02 6F 23
					39 00 00 00 00 00 08 E8 52 52 56 56 5A 5A 90
					15 00 00 00 00 00 02 6F 2A
					39 00 00 00 00 00 08 E8 90 90 90 90 90 8D 8D
					15 00 00 00 00 00 02 6F 31
					39 00 00 00 00 00 08 E8 89 89 89 00 A8 AA AA
					15 00 00 00 00 00 02 6F 38
					39 00 00 00 00 00 08 E8 AA AA AA AA AB AB AD
					15 00 00 00 00 00 02 6F 3F
					39 00 00 00 00 00 08 E8 AD B8 B8 B8 B8 B8 B8
					15 00 00 00 00 00 02 6F 46
					39 00 00 00 00 00 06 E8 B5 B5 B3 B3 B0
					// serinal number
					39 00 00 00 00 00 06 F0 55 AA 52 08 01
					39 00 00 00 00 00 08 D7 3B 1B 17 24 2F 00 62
					// corner improve
					39 00 00 00 00 00 06 F0 55 AA 52 08 07
					39 00 00 00 00 00 04 C0 07 01 F8
					15 00 00 00 00 00 02 6F 03
					39 00 00 00 00 00 05 C0 00 F0 00 00
					39 00 00 00 00 00 16 C1 3C 00 0C B1 07 39 13 26 3F E7 D0 00 00 00 00 00 00 00 00 00 00
					15 00 00 00 00 00 02 6F 15
					39 00 00 00 00 00 11 C1 83 00 00 2B 9A 9A 21 33 C0 79 2B 00 00 00 00 00
					15 00 00 00 00 00 02 6F 25
					39 00 00 00 00 00 08 C1 00 26 2B AA 22 26 00
					39 00 00 00 00 00 16 C2 3C 00 07 E9 0E 89 15 72 3F F3 84 4C 00 0B 18 A0 00 00 00 00 00
					15 00 00 00 00 00 02 6F 15
					39 00 00 00 00 00 11 C2 04 00 2C B9 AA 22 4F 33 C0 D3 8D 00 00 00 00 00
					15 00 00 00 00 00 02 6F 25
					39 00 00 00 00 00 08 C2 44 94 9A AA 22 29 00
					39 00 00 00 00 00 16 C3 3A 0F 0B 64 06 91 EE B4 00 13 8D 68 00 03 26 1C 7F FC 64 FA 44
					15 00 00 00 00 00 02 6F 15
					39 00 00 00 00 00 11 C3 89 44 94 BF 9A 97 21 33 0F 8A 2B E8 D2 00 00 00
					15 00 00 00 00 00 02 6F 25
					39 00 00 00 00 00 08 C3 00 26 2B 00 29 2D 00
					39 00 00 00 00 00 16 C4 32 0F 07 39 07 E9 F0 E2 00 02 E5 72 00 12 B9 8E 7F FC 76 CF F9
					15 00 00 00 00 00 02 6F 15
					39 00 00 00 00 00 11 C4 2D 44 0C 93 AA 22 4F 33 0F 2D 87 E8 45 00 00 00
					15 00 00 00 00 00 02 6F 25
					39 00 00 00 00 00 08 C4 44 94 99 00 29 2D 00
					39 00 00 00 00 00 16 C5 30 0F 0B D1 07 39 ED 86 3F F2 0E AA 3F F8 61 E2 00 02 02 30 E9
					15 00 00 00 00 00 02 6F 15
					39 00 00 00 00 00 11 C5 02 00 00 2B 00 2E B5 33 F0 79 D5 16 AD 00 00 00
					15 00 00 00 00 00 02 6F 25
					39 00 00 00 00 00 08 C5 44 94 9A 00 26 2D 00
					39 00 00 00 00 00 16 C6 20 0F 07 E9 07 39 F0 E2 3F F7 A8 42 3F F2 37 5E 00 02 33 22 99
					15 00 00 00 00 00 02 6F 15
					39 00 00 00 00 00 11 C6 2D 00 2C B3 00 00 2D 33 F0 D3 79 17 BB 00 00 00
					15 00 00 00 00 00 02 6F 25
					39 00 00 00 00 00 08 C6 00 00 00 00 00 00 00
					39 00 00 00 00 00 16 C7 2E 00 08 A1 07 39 0F CA 00 0A DD 90 3F F5 9E 10 00 00 00 00 00
					15 00 00 00 00 00 02 6F 15
					39 00 00 00 00 00 11 C7 89 44 94 BF 00 2E B7 33 30 89 D5 00 00 00 00 00
					15 00 00 00 00 00 02 6F 25
					39 00 00 00 00 00 08 C7 00 00 00 00 00 00 00
					39 00 00 00 00 00 16 C8 26 00 07 E9 0C B1 14 0A 00 00 00 00 3F E6 B0 00 00 00 00 00 00
					15 00 00 00 00 00 02 6F 15
					39 00 00 00 00 00 11 C8 27 44 0C 93 00 00 2D 33 30 2D 79 00 00 00 00 00
					15 00 00 00 00 00 02 6F 25
					39 00 00 00 00 00 08 C8 00 00 00 00 00 00 00
					39 00 00 00 00 00 16 C9 21 00 05 A4 05 59 00 00 3F FE 5E 98 3F FE 69 94 00 00 1E 2A 04
					15 00 00 00 00 00 02 6F 15
					39 00 00 00 00 00 11 C9 0A 22 3A 5F 00 28 4E 33 F0 DA DB 05 7E 00 00 00
					15 00 00 00 00 00 02 6F 25
					39 00 00 00 00 00 08 C9 00 00 00 00 00 00 00
					39 00 00 00 00 00 16 CA 2D 00 05 A4 05 59 00 00 3F FE 5E 98 00 00 00 00 00 00 00 00 00
					15 00 00 00 00 00 02 6F 15
					39 00 00 00 00 00 11 CA 1B 22 3A 5F 00 4F 75 33 C0 DA 25 00 00 00 00 00
					15 00 00 00 00 00 02 6F 25
					39 00 00 00 00 00 08 CA 00 00 00 00 00 00 00
					39 00 00 00 00 00 16 CB 2B 00 05 A4 05 59 00 00 00 00 00 00 00 00 00 00 7F FF E1 D5 FC
					15 00 00 00 00 00 02 6F 15
					39 00 00 00 00 00 11 CB 1B 22 60 85 00 4F 75 33 0F 26 25 FA 82 00 00 00
					15 00 00 00 00 00 02 6F 25
					39 00 00 00 00 00 08 CB 00 00 00 00 00 00 00
					39 00 00 00 00 00 16 CC 27 00 05 A4 05 59 00 00 00 00 00 00 3F FE 69 94 00 00 00 00 00
					15 00 00 00 00 00 02 6F 15
					39 00 00 00 00 00 11 CC 0A 22 60 85 00 28 4E 33 30 26 DB 00 00 00 00 00
					15 00 00 00 00 00 02 6F 25
					39 00 00 00 00 00 08 CC 00 00 00 00 00 00 00
					39 00 00 00 00 00 16 CD 21 00 27 10 27 10 00 00 3F E1 7B 80 3F E1 7B 80 00 05 F5 E1 00
					15 00 00 00 00 00 02 6F 15
					39 00 00 00 00 00 11 CD 1D 12 FA 5E 89 EB 4F 33 F0 9C 9C 27 10 00 00 00
					15 00 00 00 00 00 02 6F 25
					39 00 00 00 00 00 08 CD 00 00 00 00 00 00 00
					39 00 00 00 00 00 16 CE 27 00 27 10 27 10 00 00 00 00 00 00 3F E1 7B 80 00 00 00 00 00
					15 00 00 00 00 00 02 6F 15
					39 00 00 00 00 00 11 CE 1D 22 5F C3 89 EB 4F 33 30 64 9C 00 00 00 00 00
					15 00 00 00 00 00 02 6F 25
					39 00 00 00 00 00 08 CE 00 00 00 00 00 00 00
					39 00 00 00 00 00 16 CF 2D 00 27 10 27 10 00 00 3F E1 7B 80 00 00 00 00 00 00 00 00 00
					15 00 00 00 00 00 02 6F 15
					39 00 00 00 00 00 11 CF 46 12 FA 5E 99 50 B4 33 C0 9C 64 00 00 00 00 00
					15 00 00 00 00 00 02 6F 25
					39 00 00 00 00 00 08 CF 00 00 00 00 00 00 00
					39 00 00 00 00 00 16 D0 2B 00 27 10 27 10 00 00 00 00 00 00 00 00 00 00 7F FA 0A 1F 00
					15 00 00 00 00 00 02 6F 15
					39 00 00 00 00 00 11 D0 46 22 5F C3 99 50 B4 33 0F 64 64 D8 F0 00 00 00
					15 00 00 00 00 00 02 6F 25
					39 00 00 00 00 00 08 D0 00 00 00 00 00 00 00
					39 00 00 00 00 00 0F D1 7F FC 4B 9A 69 04 BF 7F FB 86 2B AD 04 BF
					15 00 00 00 00 00 02 6F 0E
					39 00 00 00 00 00 0F D1 00 00 00 00 00 04 C0 00 00 00 00 00 04 C0
					15 00 00 00 00 00 02 6F 1C
					39 00 00 00 00 00 0F D1 80 00 00 00 00 04 BF 80 00 00 00 00 04 BF
					15 00 00 00 00 00 02 6F 2A
					39 00 00 00 00 00 0C D1 00 02 11 8A 09 00 00 00 02 33 22
					39 00 00 00 00 00 12 D2 99 00 00 00 00 00 00 00 04 C0 7F FF E1 D5 FC 04 C0
					39 00 00 00 00 00 06 F0 55 AA 52 08 00
					15 00 00 00 00 00 02 6F 13
					39 00 00 00 00 00 19 DF 02 5E 09 4F 00 00 00 00 01 FA 08 EB 02 C3 09 B4 00 00 00 00 00 00 00 00
					//skip sequence
					39 00 00 00 00 00 06 F0 55 AA 52 08 00
					39 00 00 00 00 00 02 6F 1C
					39 00 00 00 00 00 11 BA 01 01 01 01 00 01 03 03 00 01 03 03 00 00 00 00
					39 00 00 00 00 00 02 6F 2C
					39 00 00 00 00 00 11 BA 01 01 01 01 00 01 03 0B 00 01 03 0B 00 00 00 00
					39 00 00 00 00 00 02 6F 3C
					39 00 00 00 00 00 11 BA 01 01 01 01 00 01 03 17 00 01 03 17 00 00 00 00
					39 00 00 00 00 00 02 6F 4C
					39 00 00 00 00 00 11 BA 01 01 01 01 00 01 03 77 00 01 03 77 00 00 00 00
					39 00 00 00 00 00 02 6F 5C
					39 00 00 00 00 00 11 BA 01 01 01 01 01 01 01 01 01 01 01 01 01 01 01 01
					39 00 00 00 00 00 02 6F 6C
					39 00 00 00 00 00 09 BA 00 00 00 00 00 00 00 00
					39 00 00 00 00 00 02 6F 74
					39 00 00 00 00 00 11 BA 00 01 02 03 05 0B 17 77 00 01 02 05 08 11 59 00
					39 00 00 00 00 00 02 6F 84
					39 00 00 00 00 00 11 BA 00 01 02 03 05 0B 17 77 00 01 02 05 08 11 59 00
					39 00 00 00 00 00 02 6F 94
					39 00 00 00 00 00 11 BA 00 00 00 00 00 00 00 00 00 00 00 00 00 00 00 00
					39 00 00 00 00 00 02 6F A4
					39 00 00 00 00 00 11 BA 01 01 01 01 00 00 00 02 00 00 00 03 00 00 00 00
					39 00 00 00 00 00 02 6F B4
					39 00 00 00 00 00 05 BA 94 FA A4 3A
					39 00 00 00 00 00 02 6F B8
					39 00 00 00 00 00 09 BA 00 00 00 00 11 11 11 11
					39 00 00 00 00 00 02 6F C0
					39 00 00 00 00 00 09 BA 10 00 00 00 11 11 11 11
					39 00 00 00 00 00 02 6F 08
					39 00 00 00 00 00 05 BB 01 00 00 00
					39 00 00 00 00 00 02 6F 0C
					39 00 00 00 00 00 05 BB 01 02 02 00
					39 00 00 00 00 00 02 6F 10
					39 00 00 00 00 00 05 BB 01 05 05 00
					39 00 00 00 00 00 02 6F 14
					39 00 00 00 00 00 05 BB 01 00 00 00
					39 00 00 00 00 00 02 6F 18
					39 00 00 00 00 00 06 BB 01 00 1D 1D 00
					39 00 00 00 00 00 02 6F 1D
					39 00 00 00 00 00 05 BB 01 01 01 00
					15 00 00 00 00 00 02 6F 1E
					15 00 00 00 00 00 02 B5 19 // AOD discharge on DVT OTP
					39 00 00 00 00 00 06 F0 55 AA 52 08 08
					15 00 00 00 00 00 02 6F AC
					39 00 00 00 00 00 05 BC 00 10 10 00 // OD beta3 off DVT OTP
					// VFP/VBP SOP/GOP ON
					39 00 00 00 00 00 06 F0 55 AA 52 08 00
					15 00 00 00 00 00 02 6F 0D
					15 00 00 00 00 00 02 C2 0F
					//OSC：121.9-121.2 MHz
					39 00 00 00 00 00 05 FF AA 55 A5 80
					15 00 00 00 00 00 02 6F 31
					39 00 00 00 00 00 03 F8 01 B7
					// LFCC fix
					39 00 00 00 00 00 06 F0 55 AA 52 08 00
					15 00 00 00 00 00 02 6F 08
					15 00 00 00 00 00 02 B2 C0
					39 00 00 00 00 00 06 F0 55 AA 52 08 09
					//Comp_DBVPNTS0~5 = 423h,424h,48Ah,48Bh,4F0h,4F1h
					15 00 00 00 00 00 02 6F 01
					39 00 00 00 00 00 0A BD 44 23 24 44 8A 8B 44 F0 F1
					// Fixed TE
					15 00 00 00 00 00 02 5A 00
					15 00 00 00 00 00 02 6F 03
					15 00 00 00 00 00 02 5A 00
					39 00 00 00 00 00 03 44 00 00
					15 00 00 00 00 00 02 6F 04
					39 00 00 00 00 00 0D 44 00 00 00 00 00 00 00 00 00 00 00 00
					39 00 00 00 00 00 06 F0 55 AA 52 08 00
					15 00 00 00 00 00 02 BE 47
					// TEST TE
					39 00 00 00 00 00 06 F0 55 AA 52 08 00
					15 00 00 00 00 00 02 6F 01
					15 00 00 00 00 00 02 BE 54
					//2F:30->6D:00 120Hz(Repeat 1 times) --> 120Hz
					39 00 00 00 00 00 06 F0 55 AA 52 08 00
					15 00 00 00 00 00 02 6F 03
					39 00 00 00 00 00 03 35 00 00
					15 00 00 00 00 00 02 6F 20
					39 00 00 00 00 00 09 BA 00 01 03 03 00 01 03 03
					15 00 00 00 00 00 02 6F 30
					39 00 00 00 00 00 09 BA 00 01 03 0B 00 01 03 0B
					15 00 00 00 00 00 02 6F 40
					39 00 00 00 00 00 09 BA 00 01 03 17 00 01 03 17
					15 00 00 00 00 00 02 6F 50
					39 00 00 00 00 00 09 BA 00 01 03 77 00 01 03 77
					15 00 00 00 00 00 02 2F 30
					15 00 00 00 00 00 02 6D 00 //120Hz
					// DC/PWM fix
					39 00 00 00 00 00 06 F0 55 AA 52 08 09
					15 00 00 00 00 00 02 6F 1C
					39 00 00 00 00 00 06 BD A0 89 84 02 15 //Comp0_R_Gray0~4_DBV1
					15 00 00 00 00 00 02 6F 21
					39 00 00 00 00 00 06 BD A0 89 84 02 15 //Comp0_R_Gray0~4_DBV2
					15 00 00 00 00 00 02 6F 26
					39 00 00 00 00 00 06 BD 14 09 04 86 97 //Comp0_R_Gray0~4_DBV3
					15 00 00 00 00 00 02 6F 2B
					39 00 00 00 00 00 06 BD 14 09 04 86 97 //Comp0_R_Gray0~4_DBV4
					15 00 00 00 00 00 02 6F 3A
					39 00 00 00 00 00 06 BD A0 89 84 02 15 //Comp0_G_Gray0~4_DBV1
					15 00 00 00 00 00 02 6F 3F
					39 00 00 00 00 00 06 BD A0 89 84 02 15 //Comp0_G_Gray0~4_DBV1
					15 00 00 00 00 00 02 6F 44
					39 00 00 00 00 00 06 BD 14 09 04 86 97 //Comp0_G_Gray0~4_DBV3
					15 00 00 00 00 00 02 6F 49
					39 00 00 00 00 00 06 BD 14 09 04 86 97 //Comp0_G_Gray0~4_DBV4
					15 00 00 00 00 00 02 6F 58
					39 00 00 00 00 00 06 BD A0 89 84 02 15 //Comp0_B_Gray0~4_DBV1
					15 00 00 00 00 00 02 6F 5D
					39 00 00 00 00 00 06 BD A0 89 84 02 15 //Comp0_B_Gray0~4_DBV1
					15 00 00 00 00 00 02 6F 62
					39 00 00 00 00 00 06 BD 04 09 04 86 97 //Comp0_B_Gray0~4_DBV3
					15 00 00 00 00 00 02 6F 67
					39 00 00 00 00 00 06 BD 14 09 04 86 97 //Comp0_B_Gray0~4_DBV4
					//osc fixed
					39 00 00 00 00 00 06 F0 55 AA 52 08 01
					39 00 00 00 00 00 06 C3 DD 06 20 11 FF
					15 00 00 00 00 00 02 6F 05
					39 00 00 00 00 00 06 C3 00 06 20 11 FF
					15 00 00 00 00 00 02 6F 0A
					39 00 00 00 00 00 06 C3 00 07 0E 20 06
					15 00 00 00 00 00 02 6F 0F
					39 00 00 00 00 00 06 C3 44 19 07 11 18
					15 00 00 00 00 00 02 6F 14
					39 00 00 00 00 00 06 C3 06 5C 13 07 0E
					15 00 00 00 00 00 02 6F 19
					39 00 00 00 00 00 06 C3 20 06 44 19 07
					15 00 00 00 00 00 02 6F 1E
					39 00 00 00 00 00 06 C3 0E 20 06 44 19
					15 00 00 00 00 00 02 6F 23
					39 00 00 00 00 00 06 C3 07 0E 20 06 44
					15 00 00 00 00 00 02 6F 28
					15 00 00 00 00 00 02 C3 19
					//Modify power-off timing
					39 00 00 00 00 00 06 F0 55 AA 52 08 03
					15 00 00 00 00 00 02 6F 07
					15 00 00 00 00 00 02 C6 48
					//Light On
					39 00 00 00 78 00 01 11 // Sleep out
					39 00 00 00 00 00 01 29 // Display out
				];
				oplus,dsi-aod-off-command = [
					39 00 00 40 00 00 06 F0 55 AA 52 08 00
					39 00 00 40 00 00 02 38 00
					05 00 00 40 00 00 01 2C
					39 00 00 40 00 00 03 51 00 00
					39 00 00 40 00 00 06 F0 55 AA 52 08 08
					39 00 00 40 00 00 02 BE 03
					39 00 00 40 00 00 05 FF AA 55 A5 81
					39 00 00 40 00 00 02 6F 0B
					39 00 00 00 00 00 02 FD 04 //gmaconv on
				];
				oplus,dsi-panel-aod-off-insert-black-command = [
					39 00 00 40 00 00 06 F0 55 AA 52 08 00
					39 00 00 40 00 00 02 C0 66
					39 00 00 40 00 00 06 F0 55 AA 52 08 01
					39 00 00 40 00 00 06 D2 00 11 00 00 15
					39 00 00 40 00 00 02 38 00
					39 00 00 00 00 00 03 51 00 00
				];
				oplus,dsi-ultra-low-power-aod-on-command = [
					39 00 00 40 00 00 06 F0 55 AA 52 08 00
					39 00 00 40 00 00 02 6F 18
					39 00 00 00 00 00 06 BB 01 00 02 02 00
				];
				oplus,dsi-ultra-low-power-aod-off-command = [
					39 00 00 40 00 00 06 F0 55 AA 52 08 00
					39 00 00 40 00 00 02 6F 18
					39 00 00 00 00 00 06 BB 01 00 00 00 00
				];
				oplus,dsi-hbm-on-command = [
					39 00 00 00 00 00 03 51 0F FE
				];
				oplus,dsi-hbm-off-command = [
					39 00 00 00 00 00 03 51 0D BB
				];
				oplus,dsi-adfr-min-fps-120hz-command = [
					39 00 00 40 00 00 06 F0 55 AA 52 08 09
					15 00 00 40 00 00 02 6F 1C
					39 00 00 40 00 00 06 BD A0 89 84 02 15
					15 00 00 40 00 00 02 6F 21
					39 00 00 40 00 00 06 BD A0 89 84 02 15
					15 00 00 40 00 00 02 6F 26
					39 00 00 40 00 00 06 BD 14 09 04 86 97
					15 00 00 40 00 00 02 6F 2B
					39 00 00 40 00 00 06 BD 14 09 04 86 97
					15 00 00 40 00 00 02 6F 3A
					39 00 00 40 00 00 06 BD A0 89 84 02 15
					15 00 00 40 00 00 02 6F 3F
					39 00 00 40 00 00 06 BD A0 89 84 02 15
					15 00 00 40 00 00 02 6F 44
					39 00 00 40 00 00 06 BD 14 09 04 86 97
					15 00 00 40 00 00 02 6F 49
					39 00 00 40 00 00 06 BD 14 09 04 86 97
					15 00 00 40 00 00 02 6F 58
					39 00 00 40 00 00 06 BD A0 89 84 02 15
					15 00 00 40 00 00 02 6F 5D
					39 00 00 40 00 00 06 BD A0 89 84 02 15
					15 00 00 40 00 00 02 6F 62
					39 00 00 40 00 00 06 BD 14 09 04 86 97
					15 00 00 40 00 00 02 6F 67
					39 00 00 40 00 00 06 BD 14 09 04 86 97
					39 00 00 40 00 00 02 2F 30
					39 00 00 00 00 00 02 6D 00
				];
				oplus,dsi-adfr-min-fps-30hz-command = [
					39 00 00 40 00 00 06 F0 55 AA 52 08 09
					15 00 00 40 00 00 02 6F 1C
					39 00 00 40 00 00 06 BD 90 87 82 06 1C
					15 00 00 40 00 00 02 6F 21
					39 00 00 40 00 00 06 BD 90 87 82 06 1C
					15 00 00 40 00 00 02 6F 26
					39 00 00 40 00 00 06 BD 0A 07 02 86 97
					15 00 00 40 00 00 02 6F 2B
					39 00 00 40 00 00 06 BD 0A 07 02 86 97
					15 00 00 40 00 00 02 6F 3A
					39 00 00 40 00 00 06 BD 90 87 82 06 1C
					15 00 00 40 00 00 02 6F 3F
					39 00 00 40 00 00 06 BD 90 87 82 06 1C
					15 00 00 40 00 00 02 6F 44
					39 00 00 40 00 00 06 BD 0A 07 02 86 97
					15 00 00 40 00 00 02 6F 49
					39 00 00 40 00 00 06 BD 0A 07 02 86 97
					15 00 00 40 00 00 02 6F 58
					39 00 00 40 00 00 06 BD 90 87 82 06 1C
					15 00 00 40 00 00 02 6F 5D
					39 00 00 40 00 00 06 BD 90 87 82 06 1C
					15 00 00 40 00 00 02 6F 62
					39 00 00 40 00 00 06 BD 0A 07 02 86 97
					15 00 00 40 00 00 02 6F 67
					39 00 00 40 00 00 06 BD 0A 07 02 86 97
					39 00 00 40 00 00 02 2F 30
					39 00 00 00 00 00 02 6D 03
				];
				oplus,dsi-adfr-min-fps-10hz-command = [
					39 00 00 40 00 00 06 F0 55 AA 52 08 09
					15 00 00 40 00 00 02 6F 1C
					39 00 00 40 00 00 06 BD 90 87 82 06 1C
					15 00 00 40 00 00 02 6F 21
					39 00 00 40 00 00 06 BD 90 87 82 06 1C
					15 00 00 40 00 00 02 6F 26
					39 00 00 40 00 00 06 BD 0A 07 02 86 97
					15 00 00 40 00 00 02 6F 2B
					39 00 00 40 00 00 06 BD 0A 07 02 86 97
					15 00 00 40 00 00 02 6F 3A
					39 00 00 40 00 00 06 BD 90 87 82 06 1C
					15 00 00 40 00 00 02 6F 3F
					39 00 00 40 00 00 06 BD 90 87 82 06 1C
					15 00 00 40 00 00 02 6F 44
					39 00 00 40 00 00 06 BD 0A 07 02 86 97
					15 00 00 40 00 00 02 6F 49
					39 00 00 40 00 00 06 BD 0A 07 02 86 97
					15 00 00 40 00 00 02 6F 58
					39 00 00 40 00 00 06 BD 90 87 82 06 1C
					15 00 00 40 00 00 02 6F 5D
					39 00 00 40 00 00 06 BD 90 87 82 06 1C
					15 00 00 40 00 00 02 6F 62
					39 00 00 40 00 00 06 BD 0A 07 02 86 97
					15 00 00 40 00 00 02 6F 67
					39 00 00 40 00 00 06 BD 0A 07 02 86 97
					39 00 00 40 00 00 02 2F 30
					39 00 00 00 00 00 02 6D 05
				];
				oplus,dsi-adfr-min-fps-1hz-command = [
					39 00 00 40 00 00 06 F0 55 AA 52 08 09
					15 00 00 40 00 00 02 6F 1C
					39 00 00 40 00 00 06 BD 90 87 82 06 1C
					15 00 00 40 00 00 02 6F 21
					39 00 00 40 00 00 06 BD 90 87 82 06 1C
					15 00 00 40 00 00 02 6F 26
					39 00 00 40 00 00 06 BD 0A 07 02 86 97
					15 00 00 40 00 00 02 6F 2B
					39 00 00 40 00 00 06 BD 0A 07 02 86 97
					15 00 00 40 00 00 02 6F 3A
					39 00 00 40 00 00 06 BD 90 87 82 06 1C
					15 00 00 40 00 00 02 6F 3F
					39 00 00 40 00 00 06 BD 90 87 82 06 1C
					15 00 00 40 00 00 02 6F 44
					39 00 00 40 00 00 06 BD 0A 07 02 86 97
					15 00 00 40 00 00 02 6F 49
					39 00 00 40 00 00 06 BD 0A 07 02 86 97
					15 00 00 40 00 00 02 6F 58
					39 00 00 40 00 00 06 BD 90 87 82 06 1C
					15 00 00 40 00 00 02 6F 5D
					39 00 00 40 00 00 06 BD 90 87 82 06 1C
					15 00 00 40 00 00 02 6F 62
					39 00 00 40 00 00 06 BD 0A 07 02 86 97
					15 00 00 40 00 00 02 6F 67
					39 00 00 40 00 00 06 BD 0A 07 02 86 97
					39 00 00 40 00 00 02 2F 30
					39 00 00 00 00 00 02 6D 07
				];

				oplus,dsi-timing-switch-command-state = "dsi_hs_mode";
				oplus,dsi-on-command-state = "dsi_lp_mode";
				oplus,dsi-aod-off-command-state = "dsi_ls_mode";
				oplus,dsi-panel-aod-off-insert-black-command-state = "dsi_ls_mode";
				oplus,dsi-ultra-low-power-aod-on-command-state = "dsi_ls_mode";
				oplus,dsi-ultra-low-power-aod-off-command-state = "dsi_ls_mode";
				oplus,dsi-hbm-on-command-state = "dsi_hs_mode";
				oplus,dsi-hbm-off-command-state = "dsi_hs_mode";
				oplus,dsi-adfr-min-fps-120hz-command-state = "dsi_hs_mode";
				oplus,dsi-adfr-min-fps-30hz-command-state = "dsi_hs_mode";
				oplus,dsi-adfr-min-fps-10hz-command-state = "dsi_hs_mode";
				oplus,dsi-adfr-min-fps-1hz-command-state = "dsi_hs_mode";
				oplus,dsc-params-entries = <&dsc_params>;
				oplus,spr-params-entries = <&spr_params>;
				oplus,dyn-fps {
					switch_en = <1>;
					vact_timing_fps = <120>;
					apollo_limit_superior_us = <4900>;
					apollo_limit_inferior_us = <6750>;
					apollo_transfer_time_us = <6200>;
				};
				oplus,display-mode {
					display-mode@0 {
						hdisplay = <1216>;
						vdisplay = <2640>;
						fhd-hfp = <2>;
						fhd-hsa = <26>;
						fhd-hbp = <36>;
						fhd-vfp = <100>;
						fhd-vsa = <8>;
						fhd-vbp = <76>;
						hskew = <STANDARD_ADFR>;
					};
					display-mode@1 {
						hdisplay = <1080>;
						vdisplay = <2344>;
						fhd-hfp = <2>;
						fhd-hsa = <26>;
						fhd-hbp = <36>;
						fhd-vfp = <100>;
						fhd-vsa = <8>;
						fhd-vbp = <76>;
						hskew = <STANDARD_ADFR>;
					};
				};
			};
			timing@oa_fhd_120 {
				cell-index = <3>;
				oplus,dsi-panel-framerate = <120>;
				oplus,adfr-timing-type = <2>;
				oplus,dsi-panel-pllclk = <553>;
				oplus,cmd-null-pkt-en = <0>;
				oplus,cmd-null-pkt-len = <0>;
				oplus,merge-trig-offset = <333>;
				oplus,ofp-aod-off-setbacklight-delay = <4>;
				#include "panel-ac247-p-7-a0014-dsi-cmd-common-T0.dtsi"
				oplus,dsi-timing-switch-command = [
					//120HZ
					39 00 00 40 00 00 06 F0 55 AA 52 08 00
					15 00 00 40 00 00 02 6F 03
					39 00 00 40 00 00 03 35 00 00
					15 00 00 40 00 00 02 6F 20
					39 00 00 40 00 00 09 BA 00 01 03 03 00 01 03 03
					15 00 00 40 00 00 02 6F 30
					39 00 00 40 00 00 09 BA 00 01 03 0B 00 01 03 0B
					15 00 00 40 00 00 02 6F 40
					39 00 00 40 00 00 09 BA 00 01 03 17 00 01 03 17
					15 00 00 40 00 00 02 6F 50
					39 00 00 40 00 00 09 BA 00 01 03 77 00 01 03 77
					15 00 00 40 00 00 02 2F 30
					15 00 00 40 00 00 02 6D 00 //120Hz
					// DC/PWM fix
					39 00 00 40 00 00 06 F0 55 AA 52 08 09
					15 00 00 40 00 00 02 6F 1C
					39 00 00 40 00 00 06 BD A0 89 84 02 15 //Comp0_R_Gray0~4_DBV1
					15 00 00 40 00 00 02 6F 21
					39 00 00 40 00 00 06 BD A0 89 84 02 15 //Comp0_R_Gray0~4_DBV2
					15 00 00 40 00 00 02 6F 26
					39 00 00 40 00 00 06 BD 14 09 04 86 97 //Comp0_R_Gray0~4_DBV3
					15 00 00 40 00 00 02 6F 2B
					39 00 00 40 00 00 06 BD 14 09 04 86 97 //Comp0_R_Gray0~4_DBV4
					15 00 00 40 00 00 02 6F 3A
					39 00 00 40 00 00 06 BD A0 89 84 02 15 //Comp0_G_Gray0~4_DBV1
					15 00 00 40 00 00 02 6F 3F
					39 00 00 40 00 00 06 BD A0 89 84 02 15 //Comp0_G_Gray0~4_DBV1
					15 00 00 40 00 00 02 6F 44
					39 00 00 40 00 00 06 BD 14 09 04 86 97 //Comp0_G_Gray0~4_DBV3
					15 00 00 40 00 00 02 6F 49
					39 00 00 40 00 00 06 BD 14 09 04 86 97 //Comp0_G_Gray0~4_DBV4
					15 00 00 40 00 00 02 6F 58
					39 00 00 40 00 00 06 BD A0 89 84 02 15 //Comp0_B_Gray0~4_DBV1
					15 00 00 40 00 00 02 6F 5D
					39 00 00 40 00 00 06 BD A0 89 84 02 15 //Comp0_B_Gray0~4_DBV1
					15 00 00 40 00 00 02 6F 62
					39 00 00 40 00 00 06 BD 14 09 04 86 97 //Comp0_B_Gray0~4_DBV3
					15 00 00 40 00 00 02 6F 67
					39 00 00 00 00 00 06 BD 14 09 04 86 97 //Comp0_B_Gray0~4_DBV4
				];
				oplus,dsi-on-command = [
					// init code
					39 00 00 00 00 00 05 FF AA 55 A5 81
					39 00 00 00 00 00 02 6F 0C
					39 00 00 00 00 00 02 FD 08
					39 00 00 00 00 00 02 6F 02
					39 00 00 00 00 00 02 F9 84
					39 00 00 00 00 00 02 6F 10
					39 00 00 00 00 00 02 FB 40
					39 00 00 00 00 00 05 FF AA 55 A5 80
					39 00 00 00 00 00 02 6F 48
					39 00 00 00 00 00 02 F2 00
					39 00 00 00 00 00 05 FF AA 55 A5 80
					39 00 00 00 00 00 02 6F 16
					39 00 00 00 00 00 03 F4 02 74
					39 00 00 00 00 00 05 FF AA 55 A5 80
					39 00 00 00 00 00 02 6F 42
					39 00 00 00 00 00 02 F4 00
					39 00 00 00 00 00 05 FF AA 55 A5 80
					39 00 00 00 00 00 02 6F 49
					39 00 00 00 00 00 02 F2 10
					39 00 00 00 00 00 05 FF AA 55 A5 81
					39 00 00 00 00 00 02 6F 05
					39 00 00 00 00 00 03 FE 3C 3C
					39 00 00 00 00 00 05 FF AA 55 A5 82
					39 00 00 00 00 00 02 6F 09
					39 00 00 00 00 00 02 F2 FF
					39 00 00 00 00 00 05 FF AA 55 A5 80
					39 00 00 00 00 00 02 6F 04
					39 00 00 00 00 00 02 F2 3C
					39 00 00 00 00 00 05 FF AA 55 A5 80
					39 00 00 00 00 00 02 6F 0A
					39 00 00 00 00 00 06 F6 70 70 70 70 70 //Power seq
					39 00 00 00 00 00 05 FF AA 55 A5 81
					39 00 00 00 00 00 02 6F 0D
					39 00 00 00 00 00 02 FB 80 // TE_opt
					39 00 00 00 00 00 06 F0 55 AA 52 08 01
					39 00 00 00 00 00 02 E5 00
					39 00 00 00 00 00 05 FF AA 55 A5 80
					39 00 00 00 00 00 02 6F 15
					39 00 00 00 00 00 03 F8 01 8C // DSPOSC=138.6MHz
					39 00 00 00 00 00 05 FF AA 55 A5 80
					39 00 00 00 00 00 02 6F 3E
					39 00 00 00 00 00 02 F8 00
					39 00 00 00 00 00 05 FF AA 55 A5 81
					39 00 00 00 00 00 02 6F 0B
					39 00 00 00 00 00 02 FD 04
					39 00 00 00 00 00 02 5A 01
					39 00 00 00 00 00 02 17 30
					39 00 00 00 00 00 03 5F 00 00
					39 00 00 00 00 00 02 35 00 // TE on
					39 00 00 00 00 00 0A 88 01 02 5F 09 4F 00 00 00 00
					39 00 00 00 00 00 02 53 20
					39 00 00 00 00 00 05 2A 00 00 04 BF
					39 00 00 00 00 00 05 2B 00 00 0A 4F
					39 00 00 00 00 00 02 90 03
					39 00 00 00 00 00 02 6F 01
					39 00 00 00 00 00 02 90 43
					39 00 00 00 00 00 13 91 AB A8 00 14 C2 00 02 31 02 05 00 08 05 0E 04 7B 10 E0 // VESA
					39 00 00 00 00 00 02 26 00
					39 00 00 00 00 00 02 6D 00
					39 00 00 00 00 00 02 6F 06
					39 00 00 00 00 00 02 6D 00
					//Vporch Setting
					39 00 00 00 00 00 06 F0 55 AA 52 08 00
					39 00 00 00 00 00 08 BA 00 59 00 4C 00 64 10
					39 00 00 00 00 00 02 6F 07
					39 00 00 00 00 00 08 BA 00 59 00 4C 04 0C 10
					//Chopper Setting
					39 00 00 00 00 00 06 F0 55 AA 52 08 01
					39 00 00 00 00 00 05 D9 48 50 13 40
					39 00 00 00 00 00 02 6F 23
					39 00 00 00 00 00 04 D9 C1 49 13
					39 00 00 00 00 00 06 F0 55 AA 52 08 08 //alpha LUT
					39 00 00 00 00 00 02 6F 30
					39 00 00 00 00 00 15 B2 00 00 24 B8 2C A8 34 E8 3C 78 23 B7 29 D7 33 D7 3F 27 29 96
					39 00 00 00 00 00 02 6F 44
					39 00 00 00 00 00 15 B2 34 76 22 75 2A 65 32 95 21 E4 20 53 2C E3 2C C3 26 52 20 81
					39 00 00 00 00 00 02 6F 58
					39 00 00 00 00 00 0B B2 31 31 28 30 00 1F 00 1F 00 1F
					39 00 00 00 00 00 02 6F 00
					39 00 00 00 00 00 15 B2 00 01 00 38 00 6F 00 A6 00 DD 01 14 01 5E 01 82 01 B9 01 E0
					39 00 00 00 00 00 02 6F 14
					39 00 00 00 00 00 15 B2 02 27 02 5E 02 95 02 E4 03 E5 04 8A 04 8B 05 DC 07 50 08 FC
					39 00 00 00 00 00 02 6F 28
					39 00 00 00 00 00 09 B2 0B 17 0D BB 0F FE 0F FF
					//odc on/fix
					39 00 00 00 00 00 06 F0 55 AA 52 08 08
					39 00 00 00 00 00 05 E0 21 01 01 01
					15 00 00 00 00 00 02 6F 06
					39 00 00 00 00 00 08 E0 80 30 21 32 43 54 65
					15 00 00 00 00 00 02 6F 0D
					39 00 00 00 00 00 07 E0 76 87 98 99 99 09
					39 00 00 00 00 00 08 E1 00 00 00 00 00 00 00
					15 00 00 00 00 00 02 6F 07
					39 00 00 00 00 00 08 E1 00 00 00 00 00 00 00
					15 00 00 00 00 00 02 6F 0E
					39 00 00 00 00 00 08 E1 00 00 00 00 00 00 00
					15 00 00 00 00 00 02 6F 15
					39 00 00 00 00 00 08 E1 00 00 00 00 00 00 00
					15 00 00 00 00 00 02 6F 1C
					39 00 00 00 00 00 08 E1 00 00 00 00 00 00 00
					15 00 00 00 00 00 02 6F 23
					39 00 00 00 00 00 08 E1 00 00 00 00 00 00 00
					15 00 00 00 00 00 02 6F 2A
					39 00 00 00 00 00 08 E1 00 00 00 00 00 00 00
					15 00 00 00 00 00 02 6F 31
					39 00 00 00 00 00 08 E1 00 00 00 00 00 00 00
					15 00 00 00 00 00 02 6F 38
					39 00 00 00 00 00 08 E1 00 00 00 00 00 00 00
					15 00 00 00 00 00 02 6F 3F
					39 00 00 00 00 00 08 E1 00 00 00 00 00 00 00
					15 00 00 00 00 00 02 6F 46
					39 00 00 00 00 00 08 E1 00 00 00 00 00 00 00
					15 00 00 00 00 00 02 6F 4D
					39 00 00 00 00 00 08 E1 00 00 00 00 00 00 00
					15 00 00 00 00 00 02 6F 54
					39 00 00 00 00 00 08 E1 00 00 00 00 00 00 00
					15 00 00 00 00 00 02 6F 5B
					39 00 00 00 00 00 08 E1 00 00 00 00 00 00 00
					15 00 00 00 00 00 02 6F 62
					39 00 00 00 00 00 08 E1 00 00 00 00 00 00 00
					15 00 00 00 00 00 02 6F 69
					39 00 00 00 00 00 08 E1 00 00 00 00 00 00 00
					15 00 00 00 00 00 02 6F 70
					39 00 00 00 00 00 08 E1 00 00 00 00 00 00 00
					15 00 00 00 00 00 02 6F 77
					39 00 00 00 00 00 08 E1 00 00 00 00 00 00 00
					39 00 00 00 00 00 08 E2 00 00 00 00 00 00 00
					15 00 00 00 00 00 02 6F 07
					39 00 00 00 00 00 08 E2 00 00 00 00 00 00 00
					15 00 00 00 00 00 02 6F 0E
					39 00 00 00 00 00 08 E2 00 00 00 00 00 00 00
					15 00 00 00 00 00 02 6F 15
					39 00 00 00 00 00 08 E2 00 00 00 00 00 00 00
					15 00 00 00 00 00 02 6F 1C
					39 00 00 00 00 00 08 E2 00 00 00 00 00 00 00
					15 00 00 00 00 00 02 6F 23
					39 00 00 00 00 00 08 E2 00 00 00 00 00 00 00
					15 00 00 00 00 00 02 6F 2A
					39 00 00 00 00 00 08 E2 02 04 0A 07 08 08 08
					15 00 00 00 00 00 02 6F 31
					39 00 00 00 00 00 08 E2 02 04 0A 07 08 08 08
					15 00 00 00 00 00 02 6F 38
					39 00 00 00 00 00 08 E2 02 04 0A 07 08 08 08
					15 00 00 00 00 00 02 6F 3F
					39 00 00 00 00 00 08 E2 02 04 0A 07 08 08 08
					15 00 00 00 00 00 02 6F 46
					39 00 00 00 00 00 08 E2 00 00 06 01 03 06 08
					15 00 00 00 00 00 02 6F 4D
					39 00 00 00 00 00 08 E2 02 04 0A 07 08 08 08
					15 00 00 00 00 00 02 6F 54
					39 00 00 00 00 00 08 E2 06 06 06 06 06 06 06
					15 00 00 00 00 00 02 6F 5B
					39 00 00 00 00 00 08 E2 06 06 06 06 06 06 06
					15 00 00 00 00 00 02 6F 62
					39 00 00 00 00 00 08 E2 06 06 06 06 06 06 06
					15 00 00 00 00 00 02 6F 69
					39 00 00 00 00 00 08 E2 06 06 06 06 06 06 06
					15 00 00 00 00 00 02 6F 70
					39 00 00 00 00 00 08 E2 07 07 07 07 07 07 07
					15 00 00 00 00 00 02 6F 77
					39 00 00 00 00 00 08 E2 07 07 07 07 07 07 07
					39 00 00 00 00 00 08 E3 00 00 00 00 00 00 00
					15 00 00 00 00 00 02 6F 07
					39 00 00 00 00 00 08 E3 00 00 00 00 00 00 00
					15 00 00 00 00 00 02 6F 0E
					39 00 00 00 00 00 08 E3 00 00 00 00 00 00 00
					15 00 00 00 00 00 02 6F 15
					39 00 00 00 00 00 08 E3 00 00 00 00 00 00 00
					15 00 00 00 00 00 02 6F 1C
					39 00 00 00 00 00 08 E3 00 00 00 00 00 00 00
					15 00 00 00 00 00 02 6F 23
					39 00 00 00 00 00 08 E3 00 00 00 00 00 00 00
					15 00 00 00 00 00 02 6F 2A
					39 00 00 00 00 00 08 E3 00 00 00 00 00 00 00
					15 00 00 00 00 00 02 6F 31
					39 00 00 00 00 00 08 E3 00 00 00 00 00 00 00
					15 00 00 00 00 00 02 6F 38
					39 00 00 00 00 00 08 E3 00 00 00 00 00 00 00
					15 00 00 00 00 00 02 6F 3F
					39 00 00 00 00 00 08 E3 00 00 00 00 00 00 00
					15 00 00 00 00 00 02 6F 46
					39 00 00 00 00 00 08 E3 00 00 00 00 00 00 00
					15 00 00 00 00 00 02 6F 4D
					39 00 00 00 00 00 08 E3 00 00 00 00 00 00 00
					15 00 00 00 00 00 02 6F 54
					39 00 00 00 00 00 08 E3 00 00 00 00 00 00 00
					15 00 00 00 00 00 02 6F 5B
					39 00 00 00 00 00 08 E3 00 00 00 00 00 00 00
					15 00 00 00 00 00 02 6F 62
					39 00 00 00 00 00 08 E3 00 00 00 00 00 00 00
					15 00 00 00 00 00 02 6F 69
					39 00 00 00 00 00 08 E3 00 00 00 00 00 00 00
					15 00 00 00 00 00 02 6F 70
					39 00 00 00 00 00 08 E3 00 00 00 00 00 00 00
					15 00 00 00 00 00 02 6F 77
					39 00 00 00 00 00 08 E3 00 00 00 00 00 00 00
					39 00 00 00 00 00 08 EA 00 00 00 00 00 00 00
					15 00 00 00 00 00 02 6F 07
					39 00 00 00 00 00 08 EA 00 00 00 00 00 00 00
					15 00 00 00 00 00 02 6F 0E
					39 00 00 00 00 00 08 EA 00 00 00 00 00 00 00
					15 00 00 00 00 00 02 6F 15
					39 00 00 00 00 00 07 EA 00 00 00 00 00 00
					39 00 00 00 00 00 08 E4 00 00 00 00 00 00 00
					15 00 00 00 00 00 02 6F 07
					39 00 00 00 00 00 03 E4 00 00
					39 00 00 00 00 00 08 E5 00 00 00 00 00 00 00
					15 00 00 00 00 00 02 6F 07
					39 00 00 00 00 00 03 E5 00 00
					39 00 00 00 00 00 08 E6 00 00 00 00 00 00 00
					15 00 00 00 00 00 02 6F 07
					39 00 00 00 00 00 03 E6 00 00
					39 00 00 00 00 00 08 E8 11 90 00 00 00 20 00
					15 00 00 00 00 00 02 6F 07
					39 00 00 00 00 00 08 E8 68 6C 6C 70 70 74 74
					15 00 00 00 00 00 02 6F 0E
					39 00 00 00 00 00 08 E8 78 78 7D 7D A0 A0 A1
					15 00 00 00 00 00 02 6F 15
					39 00 00 00 00 00 08 E8 A1 A1 A1 98 98 99 99
					15 00 00 00 00 00 02 6F 1C
					39 00 00 00 00 00 08 E8 99 00 48 4D 4D 4E 4E
					15 00 00 00 00 00 02 6F 23
					39 00 00 00 00 00 08 E8 52 52 56 56 5A 5A 90
					15 00 00 00 00 00 02 6F 2A
					39 00 00 00 00 00 08 E8 90 90 90 90 90 8D 8D
					15 00 00 00 00 00 02 6F 31
					39 00 00 00 00 00 08 E8 89 89 89 00 A8 AA AA
					15 00 00 00 00 00 02 6F 38
					39 00 00 00 00 00 08 E8 AA AA AA AA AB AB AD
					15 00 00 00 00 00 02 6F 3F
					39 00 00 00 00 00 08 E8 AD B8 B8 B8 B8 B8 B8
					15 00 00 00 00 00 02 6F 46
					39 00 00 00 00 00 06 E8 B5 B5 B3 B3 B0
					// serinal number
					39 00 00 00 00 00 06 F0 55 AA 52 08 01
					39 00 00 00 00 00 08 D7 3B 1B 17 24 2F 00 62
					// corner improve
					39 00 00 00 00 00 06 F0 55 AA 52 08 07
					39 00 00 00 00 00 04 C0 07 01 F8
					15 00 00 00 00 00 02 6F 03
					39 00 00 00 00 00 05 C0 00 F0 00 00
					39 00 00 00 00 00 16 C1 3C 00 0C B1 07 39 13 26 3F E7 D0 00 00 00 00 00 00 00 00 00 00
					15 00 00 00 00 00 02 6F 15
					39 00 00 00 00 00 11 C1 83 00 00 2B 9A 9A 21 33 C0 79 2B 00 00 00 00 00
					15 00 00 00 00 00 02 6F 25
					39 00 00 00 00 00 08 C1 00 26 2B AA 22 26 00
					39 00 00 00 00 00 16 C2 3C 00 07 E9 0E 89 15 72 3F F3 84 4C 00 0B 18 A0 00 00 00 00 00
					15 00 00 00 00 00 02 6F 15
					39 00 00 00 00 00 11 C2 04 00 2C B9 AA 22 4F 33 C0 D3 8D 00 00 00 00 00
					15 00 00 00 00 00 02 6F 25
					39 00 00 00 00 00 08 C2 44 94 9A AA 22 29 00
					39 00 00 00 00 00 16 C3 3A 0F 0B 64 06 91 EE B4 00 13 8D 68 00 03 26 1C 7F FC 64 FA 44
					15 00 00 00 00 00 02 6F 15
					39 00 00 00 00 00 11 C3 89 44 94 BF 9A 97 21 33 0F 8A 2B E8 D2 00 00 00
					15 00 00 00 00 00 02 6F 25
					39 00 00 00 00 00 08 C3 00 26 2B 00 29 2D 00
					39 00 00 00 00 00 16 C4 32 0F 07 39 07 E9 F0 E2 00 02 E5 72 00 12 B9 8E 7F FC 76 CF F9
					15 00 00 00 00 00 02 6F 15
					39 00 00 00 00 00 11 C4 2D 44 0C 93 AA 22 4F 33 0F 2D 87 E8 45 00 00 00
					15 00 00 00 00 00 02 6F 25
					39 00 00 00 00 00 08 C4 44 94 99 00 29 2D 00
					39 00 00 00 00 00 16 C5 30 0F 0B D1 07 39 ED 86 3F F2 0E AA 3F F8 61 E2 00 02 02 30 E9
					15 00 00 00 00 00 02 6F 15
					39 00 00 00 00 00 11 C5 02 00 00 2B 00 2E B5 33 F0 79 D5 16 AD 00 00 00
					15 00 00 00 00 00 02 6F 25
					39 00 00 00 00 00 08 C5 44 94 9A 00 26 2D 00
					39 00 00 00 00 00 16 C6 20 0F 07 E9 07 39 F0 E2 3F F7 A8 42 3F F2 37 5E 00 02 33 22 99
					15 00 00 00 00 00 02 6F 15
					39 00 00 00 00 00 11 C6 2D 00 2C B3 00 00 2D 33 F0 D3 79 17 BB 00 00 00
					15 00 00 00 00 00 02 6F 25
					39 00 00 00 00 00 08 C6 00 00 00 00 00 00 00
					39 00 00 00 00 00 16 C7 2E 00 08 A1 07 39 0F CA 00 0A DD 90 3F F5 9E 10 00 00 00 00 00
					15 00 00 00 00 00 02 6F 15
					39 00 00 00 00 00 11 C7 89 44 94 BF 00 2E B7 33 30 89 D5 00 00 00 00 00
					15 00 00 00 00 00 02 6F 25
					39 00 00 00 00 00 08 C7 00 00 00 00 00 00 00
					39 00 00 00 00 00 16 C8 26 00 07 E9 0C B1 14 0A 00 00 00 00 3F E6 B0 00 00 00 00 00 00
					15 00 00 00 00 00 02 6F 15
					39 00 00 00 00 00 11 C8 27 44 0C 93 00 00 2D 33 30 2D 79 00 00 00 00 00
					15 00 00 00 00 00 02 6F 25
					39 00 00 00 00 00 08 C8 00 00 00 00 00 00 00
					39 00 00 00 00 00 16 C9 21 00 05 A4 05 59 00 00 3F FE 5E 98 3F FE 69 94 00 00 1E 2A 04
					15 00 00 00 00 00 02 6F 15
					39 00 00 00 00 00 11 C9 0A 22 3A 5F 00 28 4E 33 F0 DA DB 05 7E 00 00 00
					15 00 00 00 00 00 02 6F 25
					39 00 00 00 00 00 08 C9 00 00 00 00 00 00 00
					39 00 00 00 00 00 16 CA 2D 00 05 A4 05 59 00 00 3F FE 5E 98 00 00 00 00 00 00 00 00 00
					15 00 00 00 00 00 02 6F 15
					39 00 00 00 00 00 11 CA 1B 22 3A 5F 00 4F 75 33 C0 DA 25 00 00 00 00 00
					15 00 00 00 00 00 02 6F 25
					39 00 00 00 00 00 08 CA 00 00 00 00 00 00 00
					39 00 00 00 00 00 16 CB 2B 00 05 A4 05 59 00 00 00 00 00 00 00 00 00 00 7F FF E1 D5 FC
					15 00 00 00 00 00 02 6F 15
					39 00 00 00 00 00 11 CB 1B 22 60 85 00 4F 75 33 0F 26 25 FA 82 00 00 00
					15 00 00 00 00 00 02 6F 25
					39 00 00 00 00 00 08 CB 00 00 00 00 00 00 00
					39 00 00 00 00 00 16 CC 27 00 05 A4 05 59 00 00 00 00 00 00 3F FE 69 94 00 00 00 00 00
					15 00 00 00 00 00 02 6F 15
					39 00 00 00 00 00 11 CC 0A 22 60 85 00 28 4E 33 30 26 DB 00 00 00 00 00
					15 00 00 00 00 00 02 6F 25
					39 00 00 00 00 00 08 CC 00 00 00 00 00 00 00
					39 00 00 00 00 00 16 CD 21 00 27 10 27 10 00 00 3F E1 7B 80 3F E1 7B 80 00 05 F5 E1 00
					15 00 00 00 00 00 02 6F 15
					39 00 00 00 00 00 11 CD 1D 12 FA 5E 89 EB 4F 33 F0 9C 9C 27 10 00 00 00
					15 00 00 00 00 00 02 6F 25
					39 00 00 00 00 00 08 CD 00 00 00 00 00 00 00
					39 00 00 00 00 00 16 CE 27 00 27 10 27 10 00 00 00 00 00 00 3F E1 7B 80 00 00 00 00 00
					15 00 00 00 00 00 02 6F 15
					39 00 00 00 00 00 11 CE 1D 22 5F C3 89 EB 4F 33 30 64 9C 00 00 00 00 00
					15 00 00 00 00 00 02 6F 25
					39 00 00 00 00 00 08 CE 00 00 00 00 00 00 00
					39 00 00 00 00 00 16 CF 2D 00 27 10 27 10 00 00 3F E1 7B 80 00 00 00 00 00 00 00 00 00
					15 00 00 00 00 00 02 6F 15
					39 00 00 00 00 00 11 CF 46 12 FA 5E 99 50 B4 33 C0 9C 64 00 00 00 00 00
					15 00 00 00 00 00 02 6F 25
					39 00 00 00 00 00 08 CF 00 00 00 00 00 00 00
					39 00 00 00 00 00 16 D0 2B 00 27 10 27 10 00 00 00 00 00 00 00 00 00 00 7F FA 0A 1F 00
					15 00 00 00 00 00 02 6F 15
					39 00 00 00 00 00 11 D0 46 22 5F C3 99 50 B4 33 0F 64 64 D8 F0 00 00 00
					15 00 00 00 00 00 02 6F 25
					39 00 00 00 00 00 08 D0 00 00 00 00 00 00 00
					39 00 00 00 00 00 0F D1 7F FC 4B 9A 69 04 BF 7F FB 86 2B AD 04 BF
					15 00 00 00 00 00 02 6F 0E
					39 00 00 00 00 00 0F D1 00 00 00 00 00 04 C0 00 00 00 00 00 04 C0
					15 00 00 00 00 00 02 6F 1C
					39 00 00 00 00 00 0F D1 80 00 00 00 00 04 BF 80 00 00 00 00 04 BF
					15 00 00 00 00 00 02 6F 2A
					39 00 00 00 00 00 0C D1 00 02 11 8A 09 00 00 00 02 33 22
					39 00 00 00 00 00 12 D2 99 00 00 00 00 00 00 00 04 C0 7F FF E1 D5 FC 04 C0
					39 00 00 00 00 00 06 F0 55 AA 52 08 00
					15 00 00 00 00 00 02 6F 13
					39 00 00 00 00 00 19 DF 02 5E 09 4F 00 00 00 00 01 FA 08 EB 02 C3 09 B4 00 00 00 00 00 00 00 00
					//skip sequence
					39 00 00 00 00 00 06 F0 55 AA 52 08 00
					39 00 00 00 00 00 02 6F 1C
					39 00 00 00 00 00 11 BA 01 01 01 01 00 01 03 03 00 01 03 03 00 00 00 00
					39 00 00 00 00 00 02 6F 2C
					39 00 00 00 00 00 11 BA 01 01 01 01 00 01 03 0B 00 01 03 0B 00 00 00 00
					39 00 00 00 00 00 02 6F 3C
					39 00 00 00 00 00 11 BA 01 01 01 01 00 01 03 17 00 01 03 17 00 00 00 00
					39 00 00 00 00 00 02 6F 4C
					39 00 00 00 00 00 11 BA 01 01 01 01 00 01 03 77 00 01 03 77 00 00 00 00
					39 00 00 00 00 00 02 6F 5C
					39 00 00 00 00 00 11 BA 01 01 01 01 01 01 01 01 01 01 01 01 01 01 01 01
					39 00 00 00 00 00 02 6F 6C
					39 00 00 00 00 00 09 BA 00 00 00 00 00 00 00 00
					39 00 00 00 00 00 02 6F 74
					39 00 00 00 00 00 11 BA 00 01 02 03 05 0B 17 77 00 01 02 05 08 11 59 00
					39 00 00 00 00 00 02 6F 84
					39 00 00 00 00 00 11 BA 00 01 02 03 05 0B 17 77 00 01 02 05 08 11 59 00
					39 00 00 00 00 00 02 6F 94
					39 00 00 00 00 00 11 BA 00 00 00 00 00 00 00 00 00 00 00 00 00 00 00 00
					39 00 00 00 00 00 02 6F A4
					39 00 00 00 00 00 11 BA 01 01 01 01 00 00 00 02 00 00 00 03 00 00 00 00
					39 00 00 00 00 00 02 6F B4
					39 00 00 00 00 00 05 BA 94 FA A4 3A
					39 00 00 00 00 00 02 6F B8
					39 00 00 00 00 00 09 BA 00 00 00 00 11 11 11 11
					39 00 00 00 00 00 02 6F C0
					39 00 00 00 00 00 09 BA 10 00 00 00 11 11 11 11
					39 00 00 00 00 00 02 6F 08
					39 00 00 00 00 00 05 BB 01 00 00 00
					39 00 00 00 00 00 02 6F 0C
					39 00 00 00 00 00 05 BB 01 02 02 00
					39 00 00 00 00 00 02 6F 10
					39 00 00 00 00 00 05 BB 01 05 05 00
					39 00 00 00 00 00 02 6F 14
					39 00 00 00 00 00 05 BB 01 00 00 00
					39 00 00 00 00 00 02 6F 18
					39 00 00 00 00 00 06 BB 01 00 1D 1D 00
					39 00 00 00 00 00 02 6F 1D
					39 00 00 00 00 00 05 BB 01 01 01 00
					15 00 00 00 00 00 02 6F 1E
					15 00 00 00 00 00 02 B5 19 // AOD discharge on DVT OTP
					39 00 00 00 00 00 06 F0 55 AA 52 08 08
					15 00 00 00 00 00 02 6F AC
					39 00 00 00 00 00 05 BC 00 10 10 00 // OD beta3 off DVT OTP
					// VFP/VBP SOP/GOP ON
					39 00 00 00 00 00 06 F0 55 AA 52 08 00
					15 00 00 00 00 00 02 6F 0D
					15 00 00 00 00 00 02 C2 0F
					//OSC：121.9-121.2 MHz
					39 00 00 00 00 00 05 FF AA 55 A5 80
					15 00 00 00 00 00 02 6F 31
					39 00 00 00 00 00 03 F8 01 B7
					// LFCC fix
					39 00 00 00 00 00 06 F0 55 AA 52 08 00
					15 00 00 00 00 00 02 6F 08
					15 00 00 00 00 00 02 B2 C0
					39 00 00 00 00 00 06 F0 55 AA 52 08 09
					//Comp_DBVPNTS0~5 = 423h,424h,48Ah,48Bh,4F0h,4F1h
					15 00 00 00 00 00 02 6F 01
					39 00 00 00 00 00 0A BD 44 23 24 44 8A 8B 44 F0 F1
					// Fixed TE
					15 00 00 00 00 00 02 5A 00
					15 00 00 00 00 00 02 6F 03
					15 00 00 00 00 00 02 5A 00
					39 00 00 00 00 00 03 44 00 00
					15 00 00 00 00 00 02 6F 04
					39 00 00 00 00 00 0D 44 00 00 00 00 00 00 00 00 00 00 00 00
					39 00 00 00 00 00 06 F0 55 AA 52 08 00
					15 00 00 00 00 00 02 BE 47
					// TEST TE
					39 00 00 00 00 00 06 F0 55 AA 52 08 00
					15 00 00 00 00 00 02 6F 01
					15 00 00 00 00 00 02 BE 54
					//2F:30->6D:00 120Hz(Repeat 1 times) --> 120Hz
					39 00 00 00 00 00 06 F0 55 AA 52 08 00
					15 00 00 00 00 00 02 6F 03
					39 00 00 00 00 00 03 35 00 00
					15 00 00 00 00 00 02 6F 20
					39 00 00 00 00 00 09 BA 00 01 03 03 00 01 03 03
					15 00 00 00 00 00 02 6F 30
					39 00 00 00 00 00 09 BA 00 01 03 0B 00 01 03 0B
					15 00 00 00 00 00 02 6F 40
					39 00 00 00 00 00 09 BA 00 01 03 17 00 01 03 17
					15 00 00 00 00 00 02 6F 50
					39 00 00 00 00 00 09 BA 00 01 03 77 00 01 03 77
					15 00 00 00 00 00 02 2F 30
					15 00 00 00 00 00 02 6D 00 //120Hz
					// DC/PWM fix
					39 00 00 00 00 00 06 F0 55 AA 52 08 09
					15 00 00 00 00 00 02 6F 1C
					39 00 00 00 00 00 06 BD A0 89 84 02 15 //Comp0_R_Gray0~4_DBV1
					15 00 00 00 00 00 02 6F 21
					39 00 00 00 00 00 06 BD A0 89 84 02 15 //Comp0_R_Gray0~4_DBV2
					15 00 00 00 00 00 02 6F 26
					39 00 00 00 00 00 06 BD 14 09 04 86 97 //Comp0_R_Gray0~4_DBV3
					15 00 00 00 00 00 02 6F 2B
					39 00 00 00 00 00 06 BD 14 09 04 86 97 //Comp0_R_Gray0~4_DBV4
					15 00 00 00 00 00 02 6F 3A
					39 00 00 00 00 00 06 BD A0 89 84 02 15 //Comp0_G_Gray0~4_DBV1
					15 00 00 00 00 00 02 6F 3F
					39 00 00 00 00 00 06 BD A0 89 84 02 15 //Comp0_G_Gray0~4_DBV1
					15 00 00 00 00 00 02 6F 44
					39 00 00 00 00 00 06 BD 14 09 04 86 97 //Comp0_G_Gray0~4_DBV3
					15 00 00 00 00 00 02 6F 49
					39 00 00 00 00 00 06 BD 14 09 04 86 97 //Comp0_G_Gray0~4_DBV4
					15 00 00 00 00 00 02 6F 58
					39 00 00 00 00 00 06 BD A0 89 84 02 15 //Comp0_B_Gray0~4_DBV1
					15 00 00 00 00 00 02 6F 5D
					39 00 00 00 00 00 06 BD A0 89 84 02 15 //Comp0_B_Gray0~4_DBV1
					15 00 00 00 00 00 02 6F 62
					39 00 00 00 00 00 06 BD 14 09 04 86 97 //Comp0_B_Gray0~4_DBV3
					15 00 00 00 00 00 02 6F 67
					39 00 00 00 00 00 06 BD 14 09 04 86 97 //Comp0_B_Gray0~4_DBV4
					//osc fixed
					39 00 00 00 00 00 06 F0 55 AA 52 08 01
					39 00 00 00 00 00 06 C3 DD 06 20 11 FF
					15 00 00 00 00 00 02 6F 05
					39 00 00 00 00 00 06 C3 00 06 20 11 FF
					15 00 00 00 00 00 02 6F 0A
					39 00 00 00 00 00 06 C3 00 07 0E 20 06
					15 00 00 00 00 00 02 6F 0F
					39 00 00 00 00 00 06 C3 44 19 07 11 18
					15 00 00 00 00 00 02 6F 14
					39 00 00 00 00 00 06 C3 06 5C 13 07 0E
					15 00 00 00 00 00 02 6F 19
					39 00 00 00 00 00 06 C3 20 06 44 19 07
					15 00 00 00 00 00 02 6F 1E
					39 00 00 00 00 00 06 C3 0E 20 06 44 19
					15 00 00 00 00 00 02 6F 23
					39 00 00 00 00 00 06 C3 07 0E 20 06 44
					15 00 00 00 00 00 02 6F 28
					15 00 00 00 00 00 02 C3 19
					//Modify power-off timing
					39 00 00 00 00 00 06 F0 55 AA 52 08 03
					15 00 00 00 00 00 02 6F 07
					15 00 00 00 00 00 02 C6 48
					//Light On
					39 00 00 00 78 00 01 11 // Sleep out
					39 00 00 00 00 00 01 29 // Display out
				];
				oplus,dsi-aod-off-command = [
					39 00 00 40 00 00 06 F0 55 AA 52 08 00
					39 00 00 40 00 00 02 38 00
					05 00 00 40 00 00 01 2C
					39 00 00 40 00 00 03 51 00 00
					39 00 00 40 00 00 06 F0 55 AA 52 08 08
					39 00 00 40 00 00 02 BE 03
					39 00 00 40 00 00 05 FF AA 55 A5 81
					39 00 00 40 00 00 02 6F 0B
					39 00 00 00 00 00 02 FD 04 //gmaconv on
				];
				oplus,dsi-panel-aod-off-insert-black-command = [
					39 00 00 40 00 00 06 F0 55 AA 52 08 00
					39 00 00 40 00 00 02 C0 66
					39 00 00 40 00 00 06 F0 55 AA 52 08 01
					39 00 00 40 00 00 06 D2 00 11 00 00 15
					39 00 00 40 00 00 02 38 00
					39 00 00 00 00 00 03 51 00 00
				];
				oplus,dsi-hbm-on-command = [
					39 00 00 00 00 00 03 51 0F FE
				];
				oplus,dsi-hbm-off-command = [
					39 00 00 00 00 00 03 51 0D BB
				];
				oplus,dsi-adfr-min-fps-120hz-command = [
					39 00 00 40 00 00 06 F0 55 AA 52 08 09
					15 00 00 40 00 00 02 6F 1C
					39 00 00 40 00 00 06 BD A0 89 84 02 15
					15 00 00 40 00 00 02 6F 21
					39 00 00 40 00 00 06 BD A0 89 84 02 15
					15 00 00 40 00 00 02 6F 26
					39 00 00 40 00 00 06 BD 14 09 04 86 97
					15 00 00 40 00 00 02 6F 2B
					39 00 00 40 00 00 06 BD 14 09 04 86 97
					15 00 00 40 00 00 02 6F 3A
					39 00 00 40 00 00 06 BD A0 89 84 02 15
					15 00 00 40 00 00 02 6F 3F
					39 00 00 40 00 00 06 BD A0 89 84 02 15
					15 00 00 40 00 00 02 6F 44
					39 00 00 40 00 00 06 BD 14 09 04 86 97
					15 00 00 40 00 00 02 6F 49
					39 00 00 40 00 00 06 BD 14 09 04 86 97
					15 00 00 40 00 00 02 6F 58
					39 00 00 40 00 00 06 BD A0 89 84 02 15
					15 00 00 40 00 00 02 6F 5D
					39 00 00 40 00 00 06 BD A0 89 84 02 15
					15 00 00 40 00 00 02 6F 62
					39 00 00 40 00 00 06 BD 14 09 04 86 97
					15 00 00 40 00 00 02 6F 67
					39 00 00 40 00 00 06 BD 14 09 04 86 97
					39 00 00 40 00 00 02 2F 30
					39 00 00 00 00 00 02 6D 00
				];
				oplus,dsi-adfr-min-fps-30hz-command = [
					39 00 00 40 00 00 06 F0 55 AA 52 08 09
					15 00 00 40 00 00 02 6F 1C
					39 00 00 40 00 00 06 BD 90 87 82 06 1C
					15 00 00 40 00 00 02 6F 21
					39 00 00 40 00 00 06 BD 90 87 82 06 1C
					15 00 00 40 00 00 02 6F 26
					39 00 00 40 00 00 06 BD 0A 07 02 86 97
					15 00 00 40 00 00 02 6F 2B
					39 00 00 40 00 00 06 BD 0A 07 02 86 97
					15 00 00 40 00 00 02 6F 3A
					39 00 00 40 00 00 06 BD 90 87 82 06 1C
					15 00 00 40 00 00 02 6F 3F
					39 00 00 40 00 00 06 BD 90 87 82 06 1C
					15 00 00 40 00 00 02 6F 44
					39 00 00 40 00 00 06 BD 0A 07 02 86 97
					15 00 00 40 00 00 02 6F 49
					39 00 00 40 00 00 06 BD 0A 07 02 86 97
					15 00 00 40 00 00 02 6F 58
					39 00 00 40 00 00 06 BD 90 87 82 06 1C
					15 00 00 40 00 00 02 6F 5D
					39 00 00 40 00 00 06 BD 90 87 82 06 1C
					15 00 00 40 00 00 02 6F 62
					39 00 00 40 00 00 06 BD 0A 07 02 86 97
					15 00 00 40 00 00 02 6F 67
					39 00 00 40 00 00 06 BD 0A 07 02 86 97
					39 00 00 40 00 00 02 2F 30
					39 00 00 00 00 00 02 6D 03
				];
				oplus,dsi-multi-te-enable-command = [
					//Multi-te
					39 00 00 40 00 00 02 2F 30
					39 00 00 40 00 00 02 6D 07
					39 00 00 40 00 00 06 F0 55 AA 52 08 00
					39 00 00 40 00 00 02 BE 47
					39 00 00 40 00 00 02 6F 03
					39 00 00 40 00 00 02 5A 44
					39 00 00 40 00 00 06 F0 55 AA 52 08 00
					39 00 00 40 00 00 02 BE 47
					39 00 00 40 00 00 02 6F 03
					39 00 00 40 00 00 02 5A 66
					39 00 00 40 00 00 02 6F 04
					39 00 00 40 00 00 0D 44 00 00 00 B0 03 A9 00 00 00 B0 03 A9
					39 00 00 40 00 00 06 F0 55 AA 52 08 00
					39 00 00 00 00 00 02 BE 47
				];
				oplus,dsi-multi-te-disable-command = [
					//Fixed-te
					39 00 00 40 00 00 02 6F 03
					39 00 00 40 00 00 02 5A 00
					39 00 00 40 00 00 02 6F 04
					39 00 00 00 00 00 0D 44 00 00 00 00 00 00 00 00 00 00 00 00
				];

				oplus,dsi-timing-switch-command-state = "dsi_hs_mode";
				oplus,dsi-on-command-state = "dsi_lp_mode";
				oplus,dsi-aod-off-command-state = "dsi_ls_mode";
				oplus,dsi-panel-aod-off-insert-black-command-state = "dsi_ls_mode";
				oplus,dsi-hbm-on-command-state = "dsi_hs_mode";
				oplus,dsi-hbm-off-command-state = "dsi_hs_mode";
				oplus,dsi-adfr-min-fps-120hz-command-state = "dsi_hs_mode";
				oplus,dsi-adfr-min-fps-30hz-command-state = "dsi_hs_mode";
				oplus,dsi-multi-te-disable-command-state = "dsi_hs_mode";
				oplus,dsi-multi-te-enable-command-state = "dsi_hs_mode";
				oplus,dsc-params-entries = <&dsc_params>;
				oplus,spr-params-entries = <&spr_params>;
				oplus,dyn-fps {
					switch_en = <1>;
					vact_timing_fps = <120>;
					apollo_limit_superior_us = <4900>;
					apollo_limit_inferior_us = <6750>;
					apollo_transfer_time_us = <6200>;
				};
				oplus,display-mode {
					oplus,display-mode@0 {
						hdisplay = <1216>;
						vdisplay = <2640>;
						fhd-hfp = <2>;
						fhd-hsa = <26>;
						fhd-hbp = <36>;
						fhd-vfp = <100>;
						fhd-vsa = <8>;
						fhd-vbp = <76>;
						hskew = <OPLUS_ADFR>;
					};
					oplus,display-mode@1 {
						hdisplay = <1080>;
						vdisplay = <2344>;
						fhd-hfp = <2>;
						fhd-hsa = <26>;
						fhd-hbp = <36>;
						fhd-vfp = <100>;
						fhd-vsa = <8>;
						fhd-vbp = <76>;
						hskew = <OPLUS_ADFR>;
					};
				};
			};
		};
	};
};

&panel_ac247_p_7_a0014_dsi_cmd {
	oplus,dsi-display-panel@1 {
		res-switch = <2>;
		/* Hardware config */
		oplus,panel-supply-entries = <&dsi_panel_pwr_supply>;
		oplus,panel-power-on-sequence = "1", "vddio", "5", "vddr", "5", "vci", "1";
		oplus,panel-power-off-sequence = "2", "vci", "5", "vddr", "5", "vddio", "1";
		reset-gpios = <&pio 90 0>;
		oplus,panel-reset-sequence = <2 10>, <1 1>, <0 1>, <1 20>;
		/* Panel config */
		oplus,dsi-serial-number-enabled = <1>;
		oplus,dsi-serial-number-index = <0>;
		oplus,dsi-serial-number-reg = <0xA3>;
		oplus,dsi-serial-number-read-count = <7>;
		oplus,dsi-serial-number-year-offset = <0>;
		oplus,partial-update-enable;
		oplus,mode-switch-h2l-delay;
		//oplus,demura-dbv-enable;
		oplus,lfcc-dbv-cfg = <1162>;
		/* PWM config */
		oplus,pwm-turbo-support = <1>; /* 0 not support, 1 with switch, 2 Global high frequency pwm without switch */
		oplus,pwm-switch-backlight-threshold = <0>;
		/* ADFR config */
		oplus-adfr-config = <0x201>;
		oplus-adfr-test-te-gpios = <&pio 103 0>;
		/* OFP config */
		oplus,ofp-fp-type = <0x410>;
		oplus,ofp-fp-local-hbm-calibration;
		oplus,ofp-longrui-aod-config = <0x0E>;
		/* ext_params */
		oplus,panel-type = <2>;
		oplus,keep_ulps = <1>;
		oplus,lane-swap-en = <0>;
		oplus,lane-swap = <
			MIPITX_PHY_LANE_0 MIPITX_PHY_LANE_1 MIPITX_PHY_LANE_3 MIPITX_PHY_LANE_2 MIPITX_PHY_LANE_CK MIPITX_PHY_LANE_0
			MIPITX_PHY_LANE_0 MIPITX_PHY_LANE_1 MIPITX_PHY_LANE_3 MIPITX_PHY_LANE_2 MIPITX_PHY_LANE_CK MIPITX_PHY_LANE_0
		>;
		oplus,lcm-color-mode = <MTK_DRM_COLOR_MODE_DISPLAY_P3>;
		oplus,output-mode = <MTK_PANEL_DSC_SINGLE_PORT>;
		oplus,panel-bpp = <10>;
		oplus,physical-width-um = <67123>;
		oplus,physical-height-um = <145728>;
		/* color */
		oplus,color-vivid-status;
		oplus,color-srgb-status;
		// oplus,color-softiris-status;
		// oplus,color-dual-panel-status;
		oplus,color-dual-brightness-status;
		oplus,color-oplus-calibrate-status;
		// oplus,color-samsung-status;
		oplus,color-loading-status;
		oplus,color-2nit-status;
		// oplus,color-nature-profession-status;
		/* ESD */
		oplus,cust-esd-check = <0>;
		oplus,esd-check-enable = <1>;
		oplus,esd_check_cmd = [
			0A
			0E
			AB
		];
		oplus,esd_check_count = [
			01
			01
			01
		];
		oplus,esd_check_value = [
			9C
			80
			00
		];
		oplus,esd_check_mask = [
			FF
			FF
			FF
		];
		/* MIPI error check config */
		/*
		 ** BIT(0): enable/disable check
		 ** BIT(1): enable/disable page switch
		 */
		oplus,mipi-err-check-config = <0x01>; // 0b0000'0111
		oplus,mipi-err-check-reg = [
			AB
		];
		oplus,mipi-err-check-value = [
			00 00
			00 40
		];
		oplus,mipi-err-check-count = [
			02
		];
		/*  32-bit binary flag
		 ** Bit value identified how to match the return value of each register.
		 ** The value 0(default) means equal, and the value 1 means not equal.
		 */
		oplus,mipi-err-check-match-modes = <0x00000000>;
	};
};
